AUTOSAR XML (schema 314)
package /DaVinci
  ecu configuration EPS: ecu-extract=EPS, ecu-sw-composition=EcuSwComposition
package /DaVinci/PKG_ClusterCAN00
  can cluster CAN00: nm-node-detection-enabled=false, nm-node-id-enabled=false, nm-repeat-message-support=false, speed=0
    physical channel CHNL: can-tp-connection-channel{addressing-format=STANDARD, data-pdu=DiagFuncReqFT_Tp__CAN00, multicast-addressing=true, tp-sdu=DCM_DiagFuncReqFT_Tp__CAN00}
      frame ABS2__CAN00: id 0x360, to EPS, frame-length=8, can-addressing-mode=STANDARD
        carries pdu ABS2__CAN00: packing-byte-order=big-endian, start-position=7
        pdu ABS2__CAN00: length=64
          signal VehSpeed_ABS2__CAN00: start 7, 12 bit, big-endian, data-type=DT_VehSpeed, init-value=C_VehSpeed, to EPS
      frame BCM1__CAN00: id 0x420, to EPS, frame-length=8, can-addressing-mode=STANDARD
        carries pdu BCM1__CAN00: packing-byte-order=big-endian, start-position=7
        pdu BCM1__CAN00: length=64
          signal BCM_Key_Sta_BCM1__CAN00: start 7, 2 bit, big-endian, data-type=DT_BCM_Key_Sta, init-value=C_BCM_Key_Sta, to EPS
      frame DiagFuncReqFT__CAN00: id 0x7D0, to EPS, frame-length=8, can-addressing-mode=STANDARD
        n pdu DiagFuncReqFT_Tp__CAN00
      frame DiagPhysReqToEPAS__CAN00: id 0x772, to EPS, frame-length=8, can-addressing-mode=STANDARD
        pdu DiagPhysReqToEPAS_Tp__CAN00: length=64
      frame DiagRespFromEPAS__CAN00: id 0x7B2, from EPS, frame-length=8, can-addressing-mode=STANDARD
        pdu DiagRespFromEPAS_Tp__CAN00: length=64
      frame ECM1__CAN00: id 0x316, to EPS, frame-length=8, can-addressing-mode=STANDARD
        carries pdu ECM1__CAN00: packing-byte-order=big-endian, start-position=7
        pdu ECM1__CAN00: length=64
          signal CAN_N_ECM1__CAN00: start 23, 16 bit, big-endian, data-type=DT_CAN_N, init-value=C_CAN_N, to EPS
          signal LV_CAN_N_ERR_ECM1__CAN00: start 1, 1 bit, big-endian, data-type=DT_LV_CAN_N_ERR, init-value=C_LV_CAN_N_ERR, to EPS
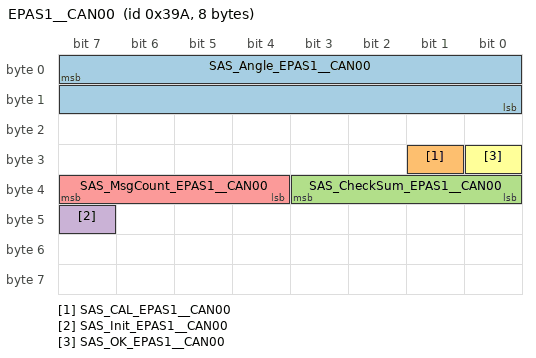
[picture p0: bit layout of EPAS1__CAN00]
      frame EPAS1__CAN00: id 0x39A, from EPS, frame-length=8, can-addressing-mode=STANDARD
        carries pdu EPAS1__CAN00: packing-byte-order=big-endian, start-position=7
        pdu EPAS1__CAN00: length=64, cyclic-timing=repeating-time=0
          transmission-mode-conditions:
            signal-in-i-pdu=SAS_Angle
            signal-in-i-pdu=SAS_CAL
            signal-in-i-pdu=SAS_CheckSum
            signal-in-i-pdu=SAS_Init
            signal-in-i-pdu=SAS_MsgCount
            signal-in-i-pdu=SAS_OK
          signal SAS_Angle_EPAS1__CAN00: start 7, 16 bit, big-endian, data-type=DT_SAS_Angle, init-value=C_SAS_Angle, transfer-property=PENDING
          signal SAS_CAL_EPAS1__CAN00: start 25, 1 bit, big-endian, data-type=DT_SAS_CAL, init-value=C_SAS_CAL, transfer-property=PENDING
          signal SAS_CheckSum_EPAS1__CAN00: start 35, 4 bit, big-endian, data-type=DT_SAS_CheckSum, init-value=C_SAS_CheckSum, transfer-property=PENDING
          signal SAS_Init_EPAS1__CAN00: start 47, 1 bit, big-endian, data-type=DT_SAS_Init, init-value=C_SAS_Init, transfer-property=PENDING
          signal SAS_MsgCount_EPAS1__CAN00: start 39, 4 bit, big-endian, data-type=DT_SAS_MsgCount, init-value=C_SAS_MsgCount, transfer-property=PENDING
          signal SAS_OK_EPAS1__CAN00: start 24, 1 bit, big-endian, data-type=DT_SAS_OK, init-value=C_SAS_OK, transfer-property=PENDING
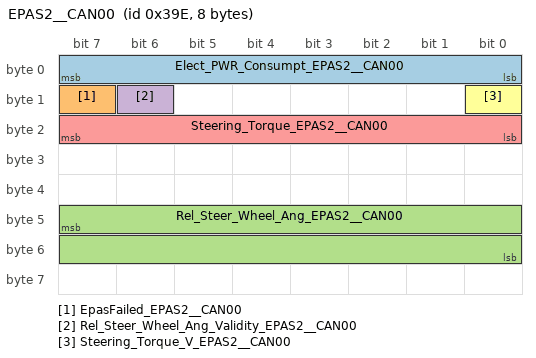
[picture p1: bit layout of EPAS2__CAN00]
      frame EPAS2__CAN00: id 0x39E, from EPS, frame-length=8, can-addressing-mode=STANDARD
        carries pdu EPAS2__CAN00: packing-byte-order=big-endian, start-position=7
        pdu EPAS2__CAN00: length=64, cyclic-timing=repeating-time=0
          transmission-mode-conditions:
            signal-in-i-pdu=Elect_PWR_Consumpt
            signal-in-i-pdu=EpasFailed
            signal-in-i-pdu=Rel_Steer_Wheel_Ang
            signal-in-i-pdu=Rel_Steer_Wheel_Ang_Validity
            signal-in-i-pdu=Steering_Torque
            signal-in-i-pdu=Steering_Torque_V
          signal Elect_PWR_Consumpt_EPAS2__CAN00: start 7, 8 bit, big-endian, data-type=DT_Elect_PWR_Consumpt, init-value=C_Elect_PWR_Consumpt, transfer-property=PENDING
          signal EpasFailed_EPAS2__CAN00: start 15, 1 bit, big-endian, data-type=DT_EpasFailed, init-value=C_EpasFailed, transfer-property=PENDING
          signal Rel_Steer_Wheel_Ang_EPAS2__CAN00: start 47, 16 bit, big-endian, transfer-property=PENDING
          signal Rel_Steer_Wheel_Ang_Validity_EPAS2__CAN00: start 14, 1 bit, big-endian, transfer-property=PENDING
          signal Steering_Torque_EPAS2__CAN00: start 23, 8 bit, big-endian, data-type=DT_Steering_Torque, init-value=C_Steering_Torque, transfer-property=PENDING
          signal Steering_Torque_V_EPAS2__CAN00: start 8, 1 bit, big-endian, data-type=DT_Steering_Torque_V, init-value=C_Steering_Torque_V, transfer-property=PENDING
      frame GliwaMaster__CAN00: id 0x7F0, to EPS, frame-length=8, can-addressing-mode=STANDARD
        pdu GliwaMaster__CAN00: length=64
      frame GliwaSlave__CAN00: id 0x7F1, from EPS, frame-length=8, can-addressing-mode=STANDARD
        pdu GliwaSlave__CAN00: length=64
      frame NMmBCM__CAN00: id 0x700, to EPS, frame-length=8, can-addressing-mode=STANDARD
        pdu NMmBCM__CAN00: length=64
      frame NMmEPAS__CAN00: id 0x707, from EPS, frame-length=8, can-addressing-mode=STANDARD
        pdu NMmEPAS__CAN00: length=64
      frame XcpMaster__CAN00: id 0x695, to EPS, frame-length=8, can-addressing-mode=STANDARD
        pdu XcpMaster__CAN00: length=64
      frame XcpSlave__CAN00: id 0x6E5, from EPS, frame-length=8, can-addressing-mode=STANDARD
        pdu XcpSlave__CAN00: length=64
      pdu triggering DCM_DiagFuncReqFT_Tp__CAN00_P: pdu=DCM_DiagFuncReqFT_Tp__CAN00, to EPS
package /DaVinci/PKG_ClusterCAN00/PKG_PDU
  dcm i pdu DCM_DiagFuncReqFT_Tp__CAN00
package /DaVinci/PKG_ECU
  ecu instance EPS: associated-i-pdu-group=[EPS_CAN00_Rx, EPS_CAN00_Tx], com-processing-period=0.001, diagnostic-address=0, sleep-mode-supported=false, wake-up-over-bus-supported=false
    can communication controller CAN00
    communication connector CAN00_EPS: channel=CHNL, comm-controller=CAN00
package /DaVinci/PKG_PDUGroup
  i pdu group EPS_CAN00_Rx: communication-direction=IN, i-pdu=[ABS2__CAN00, BCM1__CAN00, ECM1__CAN00]
  i pdu group EPS_CAN00_Tx: communication-direction=OUT, i-pdu=[DiagRespFromEPAS_Tp__CAN00, GliwaSlave__CAN00, NMmEPAS__CAN00, XcpSlave__CAN00, EPAS1__CAN00, EPAS2__CAN00]
package /ECUComposition
  ecu sw composition EcuSwComposition: ecu-extract=EPS
    9 x service component prototype:
      CDD: service-component=CDD
      ComM: service-component=ComM
      Dcm: service-component=Dcm
      Dem: service-component=Dem
      EcuM: service-component=EcuM
      NexteerLibs: service-component=NexteerLibs
      NvM: service-component=NvM
      NvMProxy: service-component=NvMProxy
      WdgM: service-component=WdgM
    service connector prototype NvMProxy_PS_NvMP_NvmBlock_EOLVehCntrOffset_AbsHwPos_EOLVehCntrOffset: application-port=ECU_Composition.AbsHwPos.EOLVehCntrOffset, service-port=NvMProxy.PS_NvMP_NvmBlock_EOLVehCntrOffset
    service connector prototype NexteerLibs_SystemTime_ActivePull_SystemTime: application-port=ECU_Composition.ActivePull.SystemTime, service-port=NexteerLibs.SystemTime
    service connector prototype NvMProxy_PS_NvMP_NvmBlock_SteerAsstDefeat_AstLmt_SteeringAsstDefeat: application-port=ECU_Composition.AstLmt.SteeringAsstDefeat, service-port=NvMProxy.PS_NvMP_NvmBlock_SteerAsstDefeat
    service connector prototype NvM_PS_Rte_NvmBlock_AvgFricLrn_AvgFricLrnData_AvgFricLrn_AvgFricLrnData: application-port=ECU_Composition.AvgFricLrn.AvgFricLrnData, service-port=NvM.PS_Rte_NvmBlock_AvgFricLrn_AvgFricLrnData
    service connector prototype NexteerLibs_SystemTime_AvgFricLrn_SystemTime: application-port=ECU_Composition.AvgFricLrn.SystemTime, service-port=NexteerLibs.SystemTime
    service connector prototype NvM_PS_Rte_NvmBlock_BatteryVoltage_OvervoltageData_BatteryVoltage_OvervoltageData: application-port=ECU_Composition.BatteryVoltage.OvervoltageData, service-port=NvM.PS_Rte_NvmBlock_BatteryVoltage_OvervoltageData
    service connector prototype NexteerLibs_SystemTime_BatteryVoltage_SystemTime: application-port=ECU_Composition.BatteryVoltage.SystemTime, service-port=NexteerLibs.SystemTime
    service connector prototype NexteerLibs_SystemTime_BkCpPc_SystemTime: application-port=ECU_Composition.BkCpPc.SystemTime, service-port=NexteerLibs.SystemTime
    service connector prototype NexteerLibs_SystemTime_BVDiag_SystemTime: application-port=ECU_Composition.BVDiag.SystemTime, service-port=NexteerLibs.SystemTime
    service connector prototype CDD_CDDPorts_CDDInterface_CDDPorts: application-port=ECU_Composition.CDDInterface.CDDPorts, service-port=CDD.CDDPorts
    service connector prototype WdgM_SE000_SE_100ms_10_CP001_ChkPtAp10_100msEnd_CP_ChkPtAp10_ChkPtAp10_100msEnd_CP: application-port=ECU_Composition.ChkPtAp10.ChkPtAp10_100msEnd_CP, service-port=WdgM.SE000_SE_100ms_10_CP001_ChkPtAp10_100msEnd_CP
    service connector prototype WdgM_SE000_SE_100ms_10_CP000_ChkPtAp10_100msStart_CP_ChkPtAp10_ChkPtAp10_100msStart_CP: application-port=ECU_Composition.ChkPtAp10.ChkPtAp10_100msStart_CP, service-port=WdgM.SE000_SE_100ms_10_CP000_ChkPtAp10_100msStart_CP
    service connector prototype WdgM_SE003_SE_10ms_10_CP001_ChkPtAp10_10msEnd_CP_ChkPtAp10_ChkPtAp10_10msEnd_CP: application-port=ECU_Composition.ChkPtAp10.ChkPtAp10_10msEnd_CP, service-port=WdgM.SE003_SE_10ms_10_CP001_ChkPtAp10_10msEnd_CP
    service connector prototype WdgM_SE003_SE_10ms_10_CP000_ChkPtAp10_10msStart_CP_ChkPtAp10_ChkPtAp10_10msStart_CP: application-port=ECU_Composition.ChkPtAp10.ChkPtAp10_10msStart_CP, service-port=WdgM.SE003_SE_10ms_10_CP000_ChkPtAp10_10msStart_CP
    service connector prototype WdgM_SE007_SE_2ms_10_CP001_ChkPtAp10_2msEnd_CP_ChkPtAp10_ChkPtAp10_2msEnd_CP: application-port=ECU_Composition.ChkPtAp10.ChkPtAp10_2msEnd_CP, service-port=WdgM.SE007_SE_2ms_10_CP001_ChkPtAp10_2msEnd_CP
    service connector prototype WdgM_SE007_SE_2ms_10_CP000_ChkPtAp10_2msStart_CP_ChkPtAp10_ChkPtAp10_2msStart_CP: application-port=ECU_Composition.ChkPtAp10.ChkPtAp10_2msStart_CP, service-port=WdgM.SE007_SE_2ms_10_CP000_ChkPtAp10_2msStart_CP
    service connector prototype WdgM_SE005_SE_4ms_10_CP001_ChkPtAp10_4msEnd_CP_ChkPtAp10_ChkPtAp10_4msEnd_CP: application-port=ECU_Composition.ChkPtAp10.ChkPtAp10_4msEnd_CP, service-port=WdgM.SE005_SE_4ms_10_CP001_ChkPtAp10_4msEnd_CP
    service connector prototype WdgM_SE005_SE_4ms_10_CP000_ChkPtAp10_4msStart_CP_ChkPtAp10_ChkPtAp10_4msStart_CP: application-port=ECU_Composition.ChkPtAp10.ChkPtAp10_4msStart_CP, service-port=WdgM.SE005_SE_4ms_10_CP000_ChkPtAp10_4msStart_CP
    service connector prototype WdgM_SE001_SE_100ms_8_CP001_ChkPtAp8_100msEnd_CP_ChkPtAp8_ChkPtAp8_100msEnd_CP: application-port=ECU_Composition.ChkPtAp8.ChkPtAp8_100msEnd_CP, service-port=WdgM.SE001_SE_100ms_8_CP001_ChkPtAp8_100msEnd_CP
    service connector prototype WdgM_SE001_SE_100ms_8_CP000_ChkPtAp8_100msStart_CP_ChkPtAp8_ChkPtAp8_100msStart_CP: application-port=ECU_Composition.ChkPtAp8.ChkPtAp8_100msStart_CP, service-port=WdgM.SE001_SE_100ms_8_CP000_ChkPtAp8_100msStart_CP
    service connector prototype WdgM_SE008_SE_2ms_8_CP001_ChkPtAp8_2msEnd_CP_ChkPtAp8_ChkPtAp8_2msEnd_CP: application-port=ECU_Composition.ChkPtAp8.ChkPtAp8_2msEnd_CP, service-port=WdgM.SE008_SE_2ms_8_CP001_ChkPtAp8_2msEnd_CP
    service connector prototype WdgM_SE008_SE_2ms_8_CP000_ChkPtAp8_2msStart_CP_ChkPtAp8_ChkPtAp8_2msStart_CP: application-port=ECU_Composition.ChkPtAp8.ChkPtAp8_2msStart_CP, service-port=WdgM.SE008_SE_2ms_8_CP000_ChkPtAp8_2msStart_CP
    service connector prototype WdgM_SE002_SE_100ms_9_CP001_ChkPtAp9_100msEnd_CP_ChkPtAp9_ChkPtAp9_100msEnd_CP: application-port=ECU_Composition.ChkPtAp9.ChkPtAp9_100msEnd_CP, service-port=WdgM.SE002_SE_100ms_9_CP001_ChkPtAp9_100msEnd_CP
    service connector prototype WdgM_SE002_SE_100ms_9_CP000_ChkPtAp9_100msStart_CP_ChkPtAp9_ChkPtAp9_100msStart_CP: application-port=ECU_Composition.ChkPtAp9.ChkPtAp9_100msStart_CP, service-port=WdgM.SE002_SE_100ms_9_CP000_ChkPtAp9_100msStart_CP
    service connector prototype WdgM_SE004_SE_10ms_9_CP001_ChkPtAp9_10msEnd_CP_ChkPtAp9_ChkPtAp9_10msEnd_CP: application-port=ECU_Composition.ChkPtAp9.ChkPtAp9_10msEnd_CP, service-port=WdgM.SE004_SE_10ms_9_CP001_ChkPtAp9_10msEnd_CP
    service connector prototype WdgM_SE004_SE_10ms_9_CP000_ChkPtAp9_10msStart_CP_ChkPtAp9_ChkPtAp9_10msStart_CP: application-port=ECU_Composition.ChkPtAp9.ChkPtAp9_10msStart_CP, service-port=WdgM.SE004_SE_10ms_9_CP000_ChkPtAp9_10msStart_CP
    service connector prototype WdgM_SE009_SE_2ms_9_CP001_ChkPtAp9_2msEnd_CP_ChkPtAp9_ChkPtAp9_2msEnd_CP: application-port=ECU_Composition.ChkPtAp9.ChkPtAp9_2msEnd_CP, service-port=WdgM.SE009_SE_2ms_9_CP001_ChkPtAp9_2msEnd_CP
    service connector prototype WdgM_SE009_SE_2ms_9_CP000_ChkPtAp9_2msStart_CP_ChkPtAp9_ChkPtAp9_2msStart_CP: application-port=ECU_Composition.ChkPtAp9.ChkPtAp9_2msStart_CP, service-port=WdgM.SE009_SE_2ms_9_CP000_ChkPtAp9_2msStart_CP
    service connector prototype WdgM_SE006_SE_4ms_9_CP001_ChkPtAp9_4msEnd_CP_ChkPtAp9_ChkPtAp9_4msEnd_CP: application-port=ECU_Composition.ChkPtAp9.ChkPtAp9_4msEnd_CP, service-port=WdgM.SE006_SE_4ms_9_CP001_ChkPtAp9_4msEnd_CP
    service connector prototype WdgM_SE006_SE_4ms_9_CP000_ChkPtAp9_4msStart_CP_ChkPtAp9_ChkPtAp9_4msStart_CP: application-port=ECU_Composition.ChkPtAp9.ChkPtAp9_4msStart_CP, service-port=WdgM.SE006_SE_4ms_9_CP000_ChkPtAp9_4msStart_CP
    service connector prototype NvMProxy_PS_NvMP_NvmBlock_CurrTempOffset_CmMtrCurr_EOLCurrTempOffset: application-port=ECU_Composition.CmMtrCurr.EOLCurrTempOffset, service-port=NvMProxy.PS_NvMP_NvmBlock_CurrTempOffset
    service connector prototype NvMProxy_PS_NvMP_NvmBlock_ShCurrCal_CmMtrCurr_EOLShCurrCal: application-port=ECU_Composition.CmMtrCurr.EOLShCurrCal, service-port=NvMProxy.PS_NvMP_NvmBlock_ShCurrCal
    service connector prototype NexteerLibs_SystemTime_ComplErr_SystemTime: application-port=ECU_Composition.ComplErr.SystemTime, service-port=NexteerLibs.SystemTime
    service connector prototype NexteerLibs_SystemTime_CtrldDisShtdn_SystemTime: application-port=ECU_Composition.CtrldDisShtdn.SystemTime, service-port=NexteerLibs.SystemTime
    service connector prototype NvMProxy_PS_NvMP_NvmBlock_EOLNomMtrParam_CurrParamComp_EOLNomMtrParamBlk: application-port=ECU_Composition.CurrParamComp.EOLNomMtrParamBlk, service-port=NvMProxy.PS_NvMP_NvmBlock_EOLNomMtrParam
    service connector prototype Dcm_DCMServices_DiagSvc_DCMServices: application-port=ECU_Composition.DiagSvc.DCMServices, service-port=Dcm.DCMServices
    service connector prototype Dcm_DidServices_0x0100_DiagSvc_DidServices_0x0100: application-port=ECU_Composition.DiagSvc.DidServices_0x0100, service-port=Dcm.DidServices_0x0100
    service connector prototype Dcm_DidServices_0xf180_DiagSvc_DidServices_0xf180: application-port=ECU_Composition.DiagSvc.DidServices_0xf180, service-port=Dcm.DidServices_0xf180
    service connector prototype Dcm_DidServices_0xf187_DiagSvc_DidServices_0xf187: application-port=ECU_Composition.DiagSvc.DidServices_0xf187, service-port=Dcm.DidServices_0xf187
    service connector prototype Dcm_DidServices_0xf18a_DiagSvc_DidServices_0xf18a: application-port=ECU_Composition.DiagSvc.DidServices_0xf18a, service-port=Dcm.DidServices_0xf18a
    service connector prototype Dcm_DidServices_0xf18c_DiagSvc_DidServices_0xf18c: application-port=ECU_Composition.DiagSvc.DidServices_0xf18c, service-port=Dcm.DidServices_0xf18c
    service connector prototype Dcm_DidServices_0xf191_DiagSvc_DidServices_0xf191: application-port=ECU_Composition.DiagSvc.DidServices_0xf191, service-port=Dcm.DidServices_0xf191
    service connector prototype Dcm_DidServices_0xf{193..195}_DiagSvc_DidServices_0xf{193..195}: application-port=ECU_Composition.DiagSvc.DidServices_0xf{193..195}, service-port=Dcm.DidServices_0xf{193..195}
    service connector prototype Dcm_DidServices_0xfd01_DiagSvc_DidServices_0xfd01: application-port=ECU_Composition.DiagSvc.DidServices_0xfd01, service-port=Dcm.DidServices_0xfd01
    service connector prototype Dcm_DidServices_0xfd02_DiagSvc_DidServices_0xfd02: application-port=ECU_Composition.DiagSvc.DidServices_0xfd02, service-port=Dcm.DidServices_0xfd02
    service connector prototype Dcm_DidServices_0xfd07_DiagSvc_DidServices_0xfd07: application-port=ECU_Composition.DiagSvc.DidServices_0xfd07, service-port=Dcm.DidServices_0xfd07
    service connector prototype Dcm_DidServices_0xfd0d_DiagSvc_DidServices_0xfd0d: application-port=ECU_Composition.DiagSvc.DidServices_0xfd0d, service-port=Dcm.DidServices_0xfd0d
    service connector prototype Dcm_DidServices_0xfd0e_DiagSvc_DidServices_0xfd0e: application-port=ECU_Composition.DiagSvc.DidServices_0xfd0e, service-port=Dcm.DidServices_0xfd0e
    service connector prototype Dcm_DidServices_0xfd{10..14}_DiagSvc_DidServices_0xfd{10..14}: application-port=ECU_Composition.DiagSvc.DidServices_0xfd{10..14}, service-port=Dcm.DidServices_0xfd{10..14}
    service connector prototype Dcm_DidServices_0xfd17_DiagSvc_DidServices_0xfd17: application-port=ECU_Composition.DiagSvc.DidServices_0xfd17, service-port=Dcm.DidServices_0xfd17
    service connector prototype Dcm_DidServices_0xfd19_DiagSvc_DidServices_0xfd19: application-port=ECU_Composition.DiagSvc.DidServices_0xfd19, service-port=Dcm.DidServices_0xfd19
    service connector prototype Dcm_DidServices_0xfd1a_DiagSvc_DidServices_0xfd1a: application-port=ECU_Composition.DiagSvc.DidServices_0xfd1a, service-port=Dcm.DidServices_0xfd1a
    service connector prototype Dcm_DidServices_0xfd1b_DiagSvc_DidServices_0xfd1b: application-port=ECU_Composition.DiagSvc.DidServices_0xfd1b, service-port=Dcm.DidServices_0xfd1b
    service connector prototype Dcm_DidServices_0xfd1c_DiagSvc_DidServices_0xfd1c: application-port=ECU_Composition.DiagSvc.DidServices_0xfd1c, service-port=Dcm.DidServices_0xfd1c
    service connector prototype Dcm_DidServices_0xfd1e_DiagSvc_DidServices_0xfd1e: application-port=ECU_Composition.DiagSvc.DidServices_0xfd1e, service-port=Dcm.DidServices_0xfd1e
    service connector prototype Dcm_DidServices_0xfd20_DiagSvc_DidServices_0xfd20: application-port=ECU_Composition.DiagSvc.DidServices_0xfd20, service-port=Dcm.DidServices_0xfd20
    service connector prototype Dcm_DidServices_0xfd21_DiagSvc_DidServices_0xfd21: application-port=ECU_Composition.DiagSvc.DidServices_0xfd21, service-port=Dcm.DidServices_0xfd21
    service connector prototype Dcm_DidServices_0xfd23_DiagSvc_DidServices_0xfd23: application-port=ECU_Composition.DiagSvc.DidServices_0xfd23, service-port=Dcm.DidServices_0xfd23
    service connector prototype Dcm_DidServices_0xfd{25..27}_DiagSvc_DidServices_0xfd{25..27}: application-port=ECU_Composition.DiagSvc.DidServices_0xfd{25..27}, service-port=Dcm.DidServices_0xfd{25..27}
    service connector prototype Dcm_DidServices_0xfd{29..31}_DiagSvc_DidServices_0xfd{29..31}: application-port=ECU_Composition.DiagSvc.DidServices_0xfd{29..31}, service-port=Dcm.DidServices_0xfd{29..31}
    service connector prototype Dcm_DidServices_0xfda{1..3}_DiagSvc_DidServices_0xfda{1..3}: application-port=ECU_Composition.DiagSvc.DidServices_0xfda{1..3}, service-port=Dcm.DidServices_0xfda{1..3}
    service connector prototype Dcm_DidServices_0xfdac_DiagSvc_DidServices_0xfdac: application-port=ECU_Composition.DiagSvc.DidServices_0xfdac, service-port=Dcm.DidServices_0xfdac
    service connector prototype Dcm_DidServices_0xfdad_DiagSvc_DidServices_0xfdad: application-port=ECU_Composition.DiagSvc.DidServices_0xfdad, service-port=Dcm.DidServices_0xfdad
    service connector prototype Dcm_DidServices_0xfdae_DiagSvc_DidServices_0xfdae: application-port=ECU_Composition.DiagSvc.DidServices_0xfdae, service-port=Dcm.DidServices_0xfdae
    service connector prototype Dcm_DidServices_0xfdaf_DiagSvc_DidServices_0xfdaf: application-port=ECU_Composition.DiagSvc.DidServices_0xfdaf, service-port=Dcm.DidServices_0xfdaf
    service connector prototype Dcm_DidServices_0xfdb{0..7}_DiagSvc_DidServices_0xfdb{0..7}: application-port=ECU_Composition.DiagSvc.DidServices_0xfdb{0..7}, service-port=Dcm.DidServices_0xfdb{0..7}
    service connector prototype Dcm_DidServices_0xfe00_DiagSvc_DidServices_0xfe00: application-port=ECU_Composition.DiagSvc.DidServices_0xfe00, service-port=Dcm.DidServices_0xfe00
    service connector prototype NvM_PS_NVM_BLOCK_CMS_ECUHWPN_DiagSvc_ECUHardwareNumber: application-port=ECU_Composition.DiagSvc.ECUHardwareNumber, service-port=NvM.PS_NVM_BLOCK_CMS_ECUHWPN
    service connector prototype NvM_PS_NVM_BLOCK_CMS_ECUSRLNUM_DiagSvc_ECUSerialNumber: application-port=ECU_Composition.DiagSvc.ECUSerialNumber, service-port=NvM.PS_NVM_BLOCK_CMS_ECUSRLNUM
    service connector prototype Dcm_RoutineServices_0xf000_DiagSvc_RoutineServices_0xf000: application-port=ECU_Composition.DiagSvc.RoutineServices_0xf000, service-port=Dcm.RoutineServices_0xf000
    service connector prototype Dcm_RoutineServices_0xf001_DiagSvc_RoutineServices_0xf001: application-port=ECU_Composition.DiagSvc.RoutineServices_0xf001, service-port=Dcm.RoutineServices_0xf001
    service connector prototype Dcm_RoutineServices_0xf{003..005}_DiagSvc_RoutineServices_0xf{003..005}: application-port=ECU_Composition.DiagSvc.RoutineServices_0xf{003..005}, service-port=Dcm.RoutineServices_0xf{003..005}
    service connector prototype Dcm_RoutineServices_0xf008_DiagSvc_RoutineServices_0xf008: application-port=ECU_Composition.DiagSvc.RoutineServices_0xf008, service-port=Dcm.RoutineServices_0xf008
    service connector prototype Dcm_RoutineServices_0xf009_DiagSvc_RoutineServices_0xf009: application-port=ECU_Composition.DiagSvc.RoutineServices_0xf009, service-port=Dcm.RoutineServices_0xf009
    service connector prototype Dcm_RoutineServices_0xf0ff_DiagSvc_RoutineServices_0xf0ff: application-port=ECU_Composition.DiagSvc.RoutineServices_0xf0ff, service-port=Dcm.RoutineServices_0xf0ff
    service connector prototype Dcm_RoutineServices_0xfee0_DiagSvc_RoutineServices_0xfee0: application-port=ECU_Composition.DiagSvc.RoutineServices_0xfee0, service-port=Dcm.RoutineServices_0xfee0
    service connector prototype Dcm_SecurityAccess_1_DiagSvc_SecurityAccess_1: application-port=ECU_Composition.DiagSvc.SecurityAccess_1, service-port=Dcm.SecurityAccess_1
    service connector prototype Dcm_SessionControl_DiagSvc_SessionControl: application-port=ECU_Composition.DiagSvc.SessionControl, service-port=Dcm.SessionControl
    service connector prototype NvM_PS_Rte_NvmBlock_DiagSvc_SparePartNumberData_DiagSvc_SparePartNumber: application-port=ECU_Composition.DiagSvc.SparePartNumber, service-port=NvM.PS_Rte_NvmBlock_DiagSvc_SparePartNumberData
    service connector prototype NvM_PS_Rte_NvmBlock_DiagSvc_SupplierIdentifierData_DiagSvc_SupplierIdentifier: application-port=ECU_Composition.DiagSvc.SupplierIdentifier, service-port=NvM.PS_Rte_NvmBlock_DiagSvc_SupplierIdentifierData
    service connector prototype NvM_PS_Rte_NvmBlock_DiagSvc_TuningSetSelectData_DiagSvc_TuningSetSelect: application-port=ECU_Composition.DiagSvc.TuningSetSelect, service-port=NvM.PS_Rte_NvmBlock_DiagSvc_TuningSetSelectData
    service connector prototype NvMProxy_PS_NvMP_NvmBlock_DigTrqTrim_DigHwTrqSENT_NvM_DigHwTrqSENTTrim_Srv: application-port=ECU_Composition.DigHwTrqSENT.NvM_DigHwTrqSENTTrim_Srv, service-port=NvMProxy.PS_NvMP_NvmBlock_DigTrqTrim
    service connector prototype NexteerLibs_SystemTime_FltInjection_SystemTime: application-port=ECU_Composition.FltInjection.SystemTime, service-port=NexteerLibs.SystemTime
    service connector prototype NvM_PS_Rte_NvmBlock_LrnEOT_LearnedEOT_LrnEOT_LearnedEOTData: application-port=ECU_Composition.LrnEOT.LearnedEOTData, service-port=NvM.PS_Rte_NvmBlock_LrnEOT_LearnedEOT
    service connector prototype NexteerLibs_SystemTime_LrnEOT_SystemTime: application-port=ECU_Composition.LrnEOT.SystemTime, service-port=NexteerLibs.SystemTime
    service connector prototype NexteerLibs_SystemTime_MtrDrvDiag_SystemTime: application-port=ECU_Composition.MtrDrvDiag.SystemTime, service-port=NexteerLibs.SystemTime
    service connector prototype NvMProxy_PS_NvMP_NvmBlock_Polarity_Polarity_Polarity: application-port=ECU_Composition.Polarity.Polarity, service-port=NvMProxy.PS_NvMP_NvmBlock_Polarity
    service connector prototype NexteerLibs_SystemTime_PwrLmtFuncCr_SystemTime: application-port=ECU_Composition.PwrLmtFuncCr.SystemTime, service-port=NexteerLibs.SystemTime
    service connector prototype NexteerLibs_SystemTime_SrlComInput_SystemTime: application-port=ECU_Composition.SrlComInput.SystemTime, service-port=NexteerLibs.SystemTime
    service connector prototype ComM_UR_ComMUser_CAN00_SrlComOutput_ComM_UserRequest: application-port=ECU_Composition.SrlComOutput.ComM_UserRequest, service-port=ComM.UR_ComMUser_CAN00
    service connector prototype Dem_IndStatus_EpasFailed_SrlComOutput_EpasFailed: application-port=ECU_Composition.SrlComOutput.EpasFailed, service-port=Dem.IndStatus_EpasFailed
    service connector prototype NexteerLibs_SystemTime_SrlComOutput_SystemTime: application-port=ECU_Composition.SrlComOutput.SystemTime, service-port=NexteerLibs.SystemTime
    service connector prototype NvMProxy_PS_NvMP_NvmBlock_CloseCheckData_StaMd_CloseCheckData: application-port=ECU_Composition.StaMd.CloseCheckData, service-port=NvMProxy.PS_NvMP_NvmBlock_CloseCheckData
    service connector prototype NvMProxy_PS_NvMP_NvmBlock_TypeHRamBuffer_StaMd_TypeHData: application-port=ECU_Composition.StaMd.TypeHData, service-port=NvMProxy.PS_NvMP_NvmBlock_TypeHRamBuffer
    service connector prototype NexteerLibs_SystemTime_StOpCtrl_SystemTime: application-port=ECU_Composition.StOpCtrl.SystemTime, service-port=NexteerLibs.SystemTime
    service connector prototype NexteerLibs_SystemTime_Sweep_SystemTime: application-port=ECU_Composition.Sweep.SystemTime, service-port=NexteerLibs.SystemTime
    service connector prototype NvM_PS_Rte_NvmBlock_ThrmlDutyCycle_ThrmlDutyCycle_FltStVal_ThrmlDutyCycle_ThrmlDutyCycle_FltStVar: application-port=ECU_Composition.ThrmlDutyCycle.ThrmlDutyCycle_FltStVar, service-port=NvM.PS_Rte_NvmBlock_ThrmlDutyCycle_ThrmlDutyCycle_FltStVal
    service connector prototype NexteerLibs_SystemTime_TmprlMon_SystemTime: application-port=ECU_Composition.TmprlMon.SystemTime, service-port=NexteerLibs.SystemTime
    service connector prototype NexteerLibs_SystemTime_TmprlMon2_SystemTime: application-port=ECU_Composition.TmprlMon2.SystemTime, service-port=NexteerLibs.SystemTime
    service connector prototype NvMProxy_PS_NvMP_NvmBlock_CogTrqCal_TrqCanc_EOLCogTrqCanc: application-port=ECU_Composition.TrqCanc.EOLCogTrqCanc, service-port=NvMProxy.PS_NvMP_NvmBlock_CogTrqCal
    service connector prototype NvMProxy_PS_NvMP_NvmBlock_CogTrqRplComp_TrqCanc_EOLCogTrqRplComp: application-port=ECU_Composition.TrqCanc.EOLCogTrqRplComp, service-port=NvMProxy.PS_NvMP_NvmBlock_CogTrqRplComp
    service connector prototype NvMProxy_PS_NvMP_NvmBlock_TorqueCmdSF_TrqCmdScl_TrqCmdScl: application-port=ECU_Composition.TrqCmdScl.TrqCmdScl, service-port=NvMProxy.PS_NvMP_NvmBlock_TorqueCmdSF
    service connector prototype NvMProxy_PS_NvMP_NvmBlock_MotPosReset_VehDyn_NVM_VehDynReset_Srv: application-port=ECU_Composition.VehDyn.NVM_VehDynReset_Srv, service-port=NvMProxy.PS_NvMP_NvmBlock_MotPosReset
    service connector prototype NexteerLibs_SystemTime_VehDyn_SystemTime: application-port=ECU_Composition.VehDyn.SystemTime, service-port=NexteerLibs.SystemTime
    service connector prototype EcuM_EcuMUsrCfg_EPS_VehPwrMd_EpsEcuMStRqst: application-port=ECU_Composition.VehPwrMd.EpsEcuMStRqst, service-port=EcuM.EcuMUsrCfg_EPS
package /ECUCompositionType
  composition type ECU_Composition
    12 x provide port:
      Com_Elect_PWR_Consumpt: unqueued-sender-com-spec{data-element=Cnt_u08, can-invalidate=false, init-value=C_Elect_PWR_Consumpt}, provided-interface=Com_Elect_PWR_Consumpt
      Com_EpasFailed: unqueued-sender-com-spec{data-element=Cnt_lgc, can-invalidate=false, init-value=C_EpasFailed}, provided-interface=Com_EpasFailed
      Com_Rel_Steer_Wheel_Ang: unqueued-sender-com-spec{data-element=Cnt_u16, can-invalidate=false, init-value=C_RELSTRWHLANGINIT_CNT_U16}, provided-interface=Com_Rel_Steer_Wheel_Ang
      Com_Rel_Steer_Wheel_Ang_Validity: unqueued-sender-com-spec{data-element=Cnt_lgc, can-invalidate=false, init-value=C_RELSTRWHLANGVALIDINIT_CNT_LGC}, provided-interface=Com_Rel_Steer_Wheel_Ang_Validity
      Com_SAS_Angle: unqueued-sender-com-spec{data-element=Cnt_u16, can-invalidate=false, init-value=C_SAS_Angle}, provided-interface=Com_SAS_Angle
      Com_SAS_CAL: unqueued-sender-com-spec{data-element=Cnt_lgc, can-invalidate=false, init-value=C_SAS_CAL}, provided-interface=Com_SAS_CAL
      Com_SAS_CheckSum: unqueued-sender-com-spec{data-element=Cnt_u08, can-invalidate=false, init-value=C_SAS_CheckSum}, provided-interface=Com_SAS_CheckSum
      Com_SAS_Init: unqueued-sender-com-spec{data-element=Cnt_lgc, can-invalidate=false, init-value=C_SAS_Init}, provided-interface=Com_SAS_Init
      Com_SAS_MsgCount: unqueued-sender-com-spec{data-element=Cnt_u08, can-invalidate=false, init-value=C_SAS_MsgCount}, provided-interface=Com_SAS_MsgCount
      Com_SAS_OK: unqueued-sender-com-spec{data-element=Cnt_lgc, can-invalidate=false, init-value=C_SAS_OK}, provided-interface=Com_SAS_OK
      Com_Steering_Torque: unqueued-sender-com-spec{data-element=Cnt_u08, can-invalidate=false, init-value=C_Steering_Torque}, provided-interface=Com_Steering_Torque
      Com_Steering_Torque_V: unqueued-sender-com-spec{data-element=Cnt_lgc, can-invalidate=false, init-value=C_Steering_Torque_V}, provided-interface=Com_Steering_Torque_V
    4 x require port:
      Com_BCM_Key_Sta: unqueued-receiver-com-spec{data-element=Cnt_enum, init-value=C_BCM_Key_Sta}, required-interface=Com_BCM_Key_Sta
      Com_CAN_N: unqueued-receiver-com-spec{data-element=Cnt_u16, init-value=C_CAN_N}, required-interface=Com_CAN_N
      Com_LV_CAN_N_ERR: unqueued-receiver-com-spec{data-element=Cnt_lgc, init-value=C_LV_CAN_N_ERR}, required-interface=Com_LV_CAN_N_ERR
      Com_VehSpeed: unqueued-receiver-com-spec{data-element=Cnt_u16, init-value=C_VehSpeed}, required-interface=Com_VehSpeed
    87 x component:
      AbsHwPos: type=Ap_AbsHwPos
      ActivePull: type=Ap_ActivePull
      ApXcp: type=Ap_ApXcp
      Assist: type=Ap_Assist
      AssistFirewall: type=Ap_AssistFirewall
      AstLmt: type=Ap_AstLmt
      AvgFricLrn: type=Ap_AvgFricLrn
      BatteryVoltage: type=Ap_BatteryVoltage
      BkCpPc: type=Sa_BkCpPc
      BVDiag: type=Ap_BVDiag
      CDDInterface: type=Sa_CDDInterface
      ChkPtAp10: type=Ap_ChkPtAp10
      ChkPtAp8: type=Ap_ChkPtAp8
      ChkPtAp9: type=Ap_ChkPtAp9
      CmMtrCurr: type=Sa_CmMtrCurr
      ComplErr: type=Ap_ComplErr
      CtrldDisShtdn: type=Ap_CtrldDisShtdn
      CtrlTemp: type=Sa_CtrlTemp
      CurrCmd: type=Ap_CurrCmd
      CurrParamComp: type=Ap_CurrParamComp
      Damping: type=Ap_Damping
      DampingFirewall: type=Ap_DampingFirewall
      DemIf: type=Ap_DemIf
      DiagMgr10: type=Ap_DiagMgr10
      DiagMgr8: type=Ap_DiagMgr8
      DiagMgr9: type=Ap_DiagMgr9
      DiagSvc: type=Ap_DiagSvc
      DigHwTrqSENT: type=Sa_DigHwTrqSENT
      DigMSB: type=Sa_DigMSB
      DigPhsReasDiag: type=Ap_DigPhsReasDiag
      ElePwr: type=Ap_ElePwr
      EOTActuatorMng: type=Ap_EOTActuatorMng
      ePWM2: type=Ap_ePWM2
      EtDmpFw: type=Ap_EtDmpFw
      FltInjection: type=Ap_FltInjection
      FrqDepDmpnInrtCmp: type=Ap_FrqDepDmpnInrtCmp
      Gsod: type=Ap_Gsod
      HaitecTrqCmd: type=Ap_HaitecTrqCmd
      HighFreqAssist: type=Ap_HighFreqAssist
      HiLoadStall: type=Ap_HiLoadStall
      HwPwUp: type=Ap_HwPwUp
      HystComp: type=Ap_HystComp
      IoHwAbsDigSig: type=IoHwAbstraction
      IoHwAbstractionUsr: type=IoHwAbstractionUsr
      LmtCod: type=Ap_LmtCod
      LrnEOT: type=Ap_LrnEOT
      MtrDrvDiag: type=Sa_MtrDrvDiag
      MtrTempEst: type=Ap_MtrTempEst
      MtrVel: type=Sa_MtrVel
      MtrVel2: type=Sa_MtrVel2
      MtrVel3: type=Sa_MtrVel3
      Nhet1: type=Cd_Nhet1
      NtWrap: type=NtWrap
      OvrVoltMon: type=Sa_OvrVoltMon
      PeakCurrEst: type=Ap_PeakCurrEst
      PICurrCntrl: type=Ap_PICurrCntrl
      Polarity: type=Ap_Polarity
      PwrLmtFuncCr: type=Ap_PwrLmtFuncCr
      QuadDet: type=Ap_QuadDet
      Return: type=Ap_Return
      ReturnFirewall: type=Ap_ReturnFirewall
      RteErrata: type=RteErrata10
      RteErrata8: type=RteErrata8
      RteErrata9: type=RteErrata9
      ShtdnMech: type=Sa_ShtdnMech
      SignlCondn: type=Ap_SignlCondn
      SrlComInput: type=Ap_SrlComInput
      SrlComOutput: type=Ap_SrlComOutput
      StabilityComp: type=Ap_StabilityComp
      StabilityComp2: type=Ap_StabilityComp2
      StaMd: type=Ap_StaMd
      StaMd8: type=Ap_StaMd8
      StaMd9: type=Ap_StaMd9
      StOpCtrl: type=Ap_StOpCtrl
      Sweep: type=Ap_Sweep
      Sweep2: type=Ap_Sweep2
      ThrmlDutyCycle: type=Ap_ThrmlDutyCycle
      TmprlMon: type=Sa_TmprlMon
      TmprlMon2: type=Sa_TmprlMon2
      TqRsDg: type=Ap_TqRsDg
      TrqCanc: type=Ap_TrqCanc
      TrqCmdScl: type=Ap_TrqCmdScl
      TuningSelAuth: type=Ap_TuningSelAuth
      uDiag: type=Cd_uDiag
      VehDyn: type=Ap_VehDyn
      VehPwrMd: type=Ap_VehPwrMd
      VehSpdLmt: type=Ap_VehSpdLmt
    connect AbsHwPos.AbsHwPos_SCom -> NtWrap.C_AbsHwPos_SCom
    connect AbsHwPos.HandwheelAuthority -> ActivePull.HandwheelAuthority
    connect AbsHwPos.HandwheelAuthority -> AvgFricLrn.HwPosAuthority
    connect AbsHwPos.HandwheelAuthority -> EOTActuatorMng.HandWheelAuth
    connect AbsHwPos.HandwheelAuthority -> EtDmpFw.HandwheelAuthority
    connect AbsHwPos.HandwheelAuthority -> LrnEOT.HandwheelAuthority
    connect AbsHwPos.HandwheelAuthority -> Return.HandwheelAuthority
    connect AbsHwPos.HandwheelAuthority -> SrlComOutput.HandwheelAuthority
    connect AbsHwPos.HandwheelAuthority -> VehDyn.HwAuth
    connect AbsHwPos.HandwheelAuthority -> VehSpdLmt.HwPosAuth
    connect AbsHwPos.HandwheelPosition -> ActivePull.HandwheelPosition
    connect AbsHwPos.HandwheelPosition -> AvgFricLrn.HwAng
    connect AbsHwPos.HandwheelPosition -> EOTActuatorMng.HandWheelPos
    connect AbsHwPos.HandwheelPosition -> EtDmpFw.HandwheelPosition
    connect AbsHwPos.HandwheelPosition -> LrnEOT.HandwheelPosition
    connect AbsHwPos.HandwheelPosition -> Return.HandwheelPosition
    connect AbsHwPos.HandwheelPosition -> ReturnFirewall.HandwheelPosition
    connect AbsHwPos.HandwheelPosition -> SrlComOutput.HandwheelPosition
    connect AbsHwPos.HandwheelPosition -> VehDyn.HandwheelPosition
    connect AbsHwPos.HandwheelPosition -> VehSpdLmt.HwPos
    connect AbsHwPos.RelHwPos -> SrlComOutput.RelHwPos
    connect AbsHwPos.RelHwPos -> VehDyn.RelHwPos
    connect AbsHwPos.SrlComHwPosStatus -> SrlComOutput.SrlComHwPosStatus
    connect ActivePull.PullCompCmd -> AstLmt.PullCompCmd
    connect ApXcp.ActiveTunOvrPtrAddr -> TuningSelAuth.ActiveTunOvrPtrAddr
    connect ApXcp.TuningSessionActPtr -> TuningSelAuth.TuningSessionActPtr
    connect Assist.BaseAssistCmd -> AssistFirewall.BaseAssistCmd
    connect Assist.BaseAssistCmd -> DampingFirewall.BaseAssistCmd
    connect Assist.BaseAssistCmd -> FrqDepDmpnInrtCmp.BaseAssistCmd
    connect Assist.BaseAssistCmd -> HystComp.BaseAssistCmd
    connect AssistFirewall.AsstFirewallActive -> DampingFirewall.AsstFirewallActive
    connect AssistFirewall.AsstFirewallActive -> StabilityComp.AsstFWActive
    connect AssistFirewall.AsstFirewallActive -> StabilityComp2.AsstFWActive
    connect AssistFirewall.CombinedAssist -> StabilityComp.CombinedAssist
    connect AssistFirewall.CombinedAssist -> StabilityComp2.CombinedAssist
    connect AstLmt.AstLmt_Scom -> HaitecTrqCmd.AstLmt_Scom
    connect AstLmt.AstLmt_Scom -> NtWrap.C_AstLmt_Scom
    connect AstLmt.PreLimitForStall -> HiLoadStall.PreLimitForStall
    connect AstLmt.PreLimitTorque -> EOTActuatorMng.PreLimitTorque
    connect AstLmt.SumLimTrqCmd -> Sweep2.InputMtrTrq
    connect AstLmt.TrqLimitMin -> TqRsDg.TrqLimitMin
    connect AvgFricLrn.FricOffset -> HystComp.FricOffset
    connect BatteryVoltage.SysC_Vecu -> Gsod.SysC_Vecu
    connect BatteryVoltage.Vecu -> CDDInterface.Vecu
    connect BatteryVoltage.Vecu -> CmMtrCurr.Vecu
    connect BatteryVoltage.Vecu -> CurrCmd.Vecu
    connect BatteryVoltage.Vecu -> ElePwr.Vecu
    connect BatteryVoltage.Vecu -> Gsod.Vecu
    connect BatteryVoltage.Vecu -> PwrLmtFuncCr.Vecu
    connect BkCpPc.CapPcDcStub -> BkCpPc.PhyCapDischarge
    connect BkCpPc.CapPcDcStub -> BkCpPc.PhyCapPrecharge
    connect BkCpPc.PwrDiscATestComplete -> HwPwUp.PwrDiscATestComplete
    connect BkCpPc.PwrDiscBTestComplete -> HwPwUp.PwrDiscBTestComplete
    connect CDDInterface.ADCMtrCurr1 -> CmMtrCurr.ADCMtrCurr1
    connect CDDInterface.ADCMtrCurr2 -> CmMtrCurr.ADCMtrCurr2
    connect CDDInterface.CorrectedElecMtrPos -> DigMSB.CorrectedElecMtrPos
    connect CDDInterface.CorrMtrCurrPosition -> CmMtrCurr.CorrMtrCurrPosition
    connect CDDInterface.CorrMtrPosElec -> DigPhsReasDiag.LRPRCorrectedMtrPosCaptured
    connect CDDInterface.CorrMtrPosElec -> Gsod.Corrected_MtrPos
    connect CDDInterface.CorrMtrPosElec -> PICurrCntrl.CorrMtrPosElec
    connect CDDInterface.CumMechMtrPos -> DigMSB.CumMechMtrPos
    connect CDDInterface.DampingSrlComSvcDft -> Damping.DefeatDampingSvc
    connect CDDInterface.DampingSrlComSvcDft -> DampingFirewall.Defeat_Damping_Svc
    connect CDDInterface.DftAsstTbl -> Assist.DftAsstTbl
    connect CDDInterface.DftAsstTbl -> AssistFirewall.Defeat_AsstTbl_Service
    connect CDDInterface.Die1RxError -> DigMSB.Die1RxError
    connect CDDInterface.Die1RxMtrPos -> DigMSB.Die1RxMtrPos
    connect CDDInterface.Die1RxRevCtr -> DigMSB.Die1RxRevCtr
    connect CDDInterface.Die1UnderVoltgFltAccum -> DigMSB.Die1UnderVoltgFltAccum
    connect CDDInterface.Die2RxError -> DigMSB.Die2RxError
    connect CDDInterface.Die2RxMtrPos -> DigMSB.Die2RxMtrPos
    connect CDDInterface.Die2RxRevCtr -> DigMSB.Die2RxRevCtr
    connect CDDInterface.DwnldAsstGain -> Assist.DwnldAsstGain
    connect CDDInterface.EnergyModeState -> DigMSB.EnergyModeState
    connect CDDInterface.EngONSrlComSvcDft -> VehPwrMd.EngONSrlComSvcDft
    connect CDDInterface.EOTImpactSrlComSvcDft -> EOTActuatorMng.EOTDisable
    connect CDDInterface.EOTImpactSrlComSvcDft -> EtDmpFw.EOTDisable
    connect CDDInterface.EOTThermalSrlComSvcDft -> HiLoadStall.DftStallLimit
    connect CDDInterface.ExpectedOnTimeA -> DigPhsReasDiag.ExpectedOnTimeA
    connect CDDInterface.ExpectedOnTimeB -> DigPhsReasDiag.ExpectedOnTimeB
    connect CDDInterface.ExpectedOnTimeC -> DigPhsReasDiag.ExpectedOnTimeC
    connect CDDInterface.FreqDepDmpSrlComSvcDft -> DampingFirewall.FreqDepDmpSrlComSvcDft
    connect CDDInterface.FreqDepDmpSrlComSvcDft -> FrqDepDmpnInrtCmp.FreqDepDmpSrlComSvcDft
    connect CDDInterface.FricLrnSrlComSvcDft -> AvgFricLrn.DefeatFricLearning
    connect CDDInterface.HystCompSrlComSvcDft -> HystComp.DefeatHystService
    connect CDDInterface.IgnCnt -> DiagMgr10.IgnCnt
    connect CDDInterface.IgnCnt -> DiagMgr8.IgnCnt
    connect CDDInterface.IgnCnt -> DiagMgr9.IgnCnt
    connect CDDInterface.LimitSrlComSvcDft -> AstLmt.DefeatLimitService
    connect CDDInterface.LRPRPhaseadvanceCaptured -> DigPhsReasDiag.LRPRPhaseadvanceCaptured
    connect CDDInterface.MeasuredOnTimeA -> DigPhsReasDiag.MeasuredOnTimeA
    connect CDDInterface.MeasuredOnTimeB -> DigPhsReasDiag.MeasuredOnTimeB
    connect CDDInterface.MeasuredOnTimeC -> DigPhsReasDiag.MeasuredOnTimeC
    connect CDDInterface.MEC -> AbsHwPos.ManufMode
    connect CDDInterface.MEC -> AssistFirewall.MEC_Counter
    connect CDDInterface.MEC -> CmMtrCurr.MEC
    connect CDDInterface.MEC -> DampingFirewall.MEC_Counter
    connect CDDInterface.MEC -> DiagMgr10.MEC
    connect CDDInterface.MEC -> DiagMgr8.MEC
    connect CDDInterface.MEC -> DiagMgr9.MEC
    connect CDDInterface.MEC -> DiagSvc.MEC
    connect CDDInterface.MEC -> DigHwTrqSENT.MECCounter
    connect CDDInterface.MEC -> EtDmpFw.MEC_Counter
    connect CDDInterface.MEC -> ReturnFirewall.MEC_Counter
    connect CDDInterface.MEC -> SrlComInput.MEC
    connect CDDInterface.MechMtrPos1 -> VehDyn.MechMtrPos1
    connect CDDInterface.MechMtrPos1TimeStamp -> MtrVel2.MechMtrPos1Timestamp
    connect CDDInterface.MechMtrPos2TimeStamp -> MtrVel.MechMtrPos2Timestamp
    connect CDDInterface.MfgDiagInhibit -> DiagMgr10.MfgDiagInhibit
    connect CDDInterface.MfgDiagInhibit -> DiagMgr8.MfgDiagInhibit
    connect CDDInterface.MfgDiagInhibit -> DiagMgr9.MfgDiagInhibit
    connect CDDInterface.ModIdxFinal -> DigPhsReasDiag.LRPRModulationIndexCaptured
    connect CDDInterface.MtrCurrDax -> ElePwr.MtrCurrDax
    connect CDDInterface.MtrCurrDax -> PeakCurrEst.MtrCurrDax
    connect CDDInterface.MtrCurrK1 -> CmMtrCurr.MtrCurrK1
    connect CDDInterface.MtrCurrK2 -> CmMtrCurr.MtrCurrK2
    connect CDDInterface.MtrCurrQax -> ElePwr.MtrCurrQax
    connect CDDInterface.MtrCurrQax -> PeakCurrEst.MtrCurrQax
    connect CDDInterface.MtrVoltDax -> ElePwr.MtrVoltDax
    connect CDDInterface.MtrVoltQax -> ElePwr.MtrVoltQax
    connect CDDInterface.PullCompSrlComSvcDft -> ActivePull.DisableLearning
    connect CDDInterface.PullCompSrlComSvcDft -> ActivePull.DisableOutput
    connect CDDInterface.ReturnSrlComSvcDft -> Return.DefeatReturnSvc
    connect CDDInterface.ReturnSrlComSvcDft -> ReturnFirewall.Defeat_Return_Svc
    connect CDDInterface.RxMsgsSrlComSvcDft -> SrlComInput.RxMsgsSrlComSvcDft
    connect CDDInterface.RxMtrPosParityAccum -> DigMSB.RxMtrPosParityAccum
    connect CDDInterface.SrlComSvcDft -> CmMtrCurr.SrlComSvcDft
    connect CDDInterface.SysCCorrMtrPosElec -> Gsod.SysC_Corrected_MtrPos
    connect CDDInterface.SysCVSwitchADC -> IoHwAbstractionUsr.SysCVSwitchADC
    connect CDDInterface.ThermalDCSrlComSvcDft -> ThrmlDutyCycle.DefeatDutySvc
    connect CDDInterface.TrqRmpSrlComSvcDft -> StOpCtrl.RampSrlComSvcDft
    connect CDDInterface.UncorrMechMtrPos1 -> DigMSB.UncorrMechMtrPos1
    connect CmMtrCurr.CmMtrCurr_SCom -> NtWrap.C_CmMtrCurr_SCom
    connect CmMtrCurr.ComOffset -> CDDInterface.CommOffset
    connect CmMtrCurr.CurrentGainSvc -> CurrCmd.CurrentGainSvc
    connect CmMtrCurr.MtrCurr1TempOffset -> CDDInterface.MtrCurr1TempOffset
    connect CmMtrCurr.MtrCurr2TempOffset -> CDDInterface.MtrCurr2TempOffset
    connect ComplErr.ComplErr -> AbsHwPos.ComplError
    connect CtrldDisShtdn.CntDisMtrTrqCmdCRF -> AvgFricLrn.CRFMtrTrq
    connect CtrldDisShtdn.CntDisMtrTrqCmdCRF -> ComplErr.TorqueCmdCRF
    connect CtrldDisShtdn.CntDisMtrTrqCmdCRF -> Gsod.Torque_Cmd_CRF
    connect CtrldDisShtdn.CntDisMtrTrqCmdCRF -> VehDyn.TorqueCmdCRF
    connect CtrldDisShtdn.CntDisMtrTrqCmdMRF -> DiagMgr10.MtrTrq
    connect CtrldDisShtdn.CntDisMtrTrqCmdMRF -> DiagMgr8.MtrTrq
    connect CtrldDisShtdn.CntDisMtrTrqCmdMRF -> DiagMgr9.MtrTrq
    connect CtrldDisShtdn.CntDisMtrTrqCmdMRF -> Gsod.Torque_Cmd_MRF
    connect CtrldDisShtdn.CntDisMtrTrqCmdMRF -> PwrLmtFuncCr.CntDisMtrTrqCmdMRF
    connect CtrldDisShtdn.CtrldDmpStsCmp -> ePWM2.CtrldDmpStsCmp
    connect CtrldDisShtdn.CtrldDmpStsCmp -> StaMd.ControlledDampStatusComplete
    connect CtrldDisShtdn.CtrldDmpStsCmp -> StaMd8.ControlledDampStatusComplete
    connect CtrldDisShtdn.SysC_CRFMtrTrqCmd -> Gsod.SysC_Torque_Cmd_CRF
    connect CtrldDisShtdn.SysC_MRFMtrTrqCmd -> Gsod.SysC_Torque_Cmd_MRF
    connect CtrlTemp.FiltMeasTemp -> CmMtrCurr.FiltCntrlTemp
    connect CtrlTemp.FiltMeasTemp -> MtrTempEst.CtrlTempFinal
    connect CtrlTemp.FiltMeasTemp -> ThrmlDutyCycle.FiltMeasTemp
    connect CurrCmd.MtrCurrAngle -> CmMtrCurr.MtrCurrAngle
    connect CurrCmd.MtrCurrDaxRef -> CurrParamComp.MtrCurrDaxRef
    connect CurrCmd.MtrCurrDaxRef -> PICurrCntrl.MtrCurrDaxRef
    connect CurrCmd.MtrCurrDaxRef -> TrqCanc.MtrCurrDaxRef
    connect CurrCmd.MtrCurrQaxRef -> CurrParamComp.MtrCurrQaxRef
    connect CurrCmd.MtrCurrQaxRef -> TrqCanc.MtrCurrQaxRef
    connect CurrCmd.MtrTrqCmdSign -> CDDInterface.MtrTrqCmdSign
    connect CurrParamComp.EstKe -> CurrCmd.EstKe
    connect CurrParamComp.EstKe -> PICurrCntrl.EstKe
    connect CurrParamComp.EstKe -> PwrLmtFuncCr.EstKe
    connect CurrParamComp.EstKe -> TrqCanc.EstKe
    connect CurrParamComp.EstLd -> CurrCmd.EstLd
    connect CurrParamComp.EstLq -> CurrCmd.EstLq
    connect CurrParamComp.EstR -> CurrCmd.EstR
    connect CurrParamComp.EstR -> PICurrCntrl.EstR
    connect CurrParamComp.SCom_EOLNomMtrParam -> NtWrap.C_SCom_EOLNomMtrParam
    connect Damping.DampingCmd -> DampingFirewall.DampingCmd
    connect DampingFirewall.CombinedDamping -> AstLmt.CombinedDamping
    connect DemIf.DemIf -> DiagMgr9.DemIf
    connect DiagMgr10.DiagRampRate -> StOpCtrl.DiagRampRate
    connect DiagMgr10.DiagRampValue -> StOpCtrl.DiagRampValue
    connect DiagMgr10.DiagRmpToZeroActive -> StaMd.FTerm
    connect DiagMgr10.DiagRmpToZeroActive -> StaMd8.FTerm
    connect DiagMgr10.DiagRmpToZeroActive -> StOpCtrl.DiagStsDiagRmpActive
    connect DiagMgr10.DiagStsCtrldDisRmpPres -> CtrldDisShtdn.DiagStsF2Active
    connect DiagMgr10.DiagStsCtrldDisRmpPres -> ePWM2.DiagStsCtrldDisRmpPres
    connect DiagMgr10.DiagStsDefTemp -> CtrlTemp.DiagStsTempRdPrf
    connect DiagMgr10.DiagStsDefVehSpd -> SrlComInput.DefaultVehSpd
    connect DiagMgr10.DiagStsHWASbSystmFltPres -> AbsHwPos.DiagStatusHwPosReducedPerf
    connect DiagMgr10.DiagStsHWASbSystmFltPres -> LrnEOT.DiagStsHwPosDis
    connect DiagMgr10.DiagStsHWASbSystmFltPres -> Return.DiagStsHwPosDis
    connect DiagMgr10.DiagStsNonRecRmpToZeroFltPres -> ePWM2.DiagStsNonRecRmpToZeroFltPres
    connect DiagMgr10.NxtrDiagMgr10 -> AbsHwPos.NxtrDiagMgr
    connect DiagMgr10.NxtrDiagMgr10 -> AssistFirewall.NxtrDiagMgr
    connect DiagMgr10.NxtrDiagMgr10 -> CmMtrCurr.NxtrDiagMgr
    connect DiagMgr10.NxtrDiagMgr10 -> DampingFirewall.NxtrDiagMgr
    connect DiagMgr10.NxtrDiagMgr10 -> DigHwTrqSENT.NxtrDiagMgr
    connect DiagMgr10.NxtrDiagMgr10 -> DigMSB.NxtrDiagMgr
    connect DiagMgr10.NxtrDiagMgr10 -> DigPhsReasDiag.NxtrDiagMgr
    connect DiagMgr10.NxtrDiagMgr10 -> Gsod.NxtrDiagMgr
    connect DiagMgr10.NxtrDiagMgr10 -> IoHwAbstractionUsr.NxtrDiagMgr
    connect DiagMgr10.NxtrDiagMgr10 -> MtrDrvDiag.NxtrDiagMgr
    connect DiagMgr10.NxtrDiagMgr10 -> MtrVel.NxtrDiagMgr
    connect DiagMgr10.NxtrDiagMgr10 -> Nhet1.NxtrDiagMgr
    connect DiagMgr10.NxtrDiagMgr10 -> OvrVoltMon.NxtrDiagMgr
    connect DiagMgr10.NxtrDiagMgr10 -> Polarity.NxtrDiagMgr
    connect DiagMgr10.NxtrDiagMgr10 -> PwrLmtFuncCr.NxtrDiagMgr
    connect DiagMgr10.NxtrDiagMgr10 -> ReturnFirewall.NxtrDiagMgr
    connect DiagMgr10.NxtrDiagMgr10 -> StabilityComp.NxtrDiagMgr
    connect DiagMgr10.NxtrDiagMgr10 -> StaMd.NxtrDiagMgr
    connect DiagMgr10.NxtrDiagMgr10 -> TmprlMon.NxtrDiagMgr
    connect DiagMgr10.NxtrDiagMgr10 -> TqRsDg.NxtrDiagMgr
    connect DiagMgr10.NxtrDiagMgr10 -> uDiag.NxtrDiagMgr
    connect DiagMgr10.NxtrDiagMgr10 -> VehDyn.NxtrDiagMgr
    connect DiagMgr8.NxtrDiagMgr8 -> MtrVel2.NxtrDiagMgr
    connect DiagMgr8.NxtrDiagMgr8 -> StaMd8.NxtrDiagMgr
    connect DiagMgr9.DiagMgr_StaCtrl -> StaMd9.DiagMgr_StaCtrl
    connect DiagMgr9.NxtrDiagMgr9 -> AvgFricLrn.NxtrDiagMgr
    connect DiagMgr9.NxtrDiagMgr9 -> BatteryVoltage.NxtrDiagMgr
    connect DiagMgr9.NxtrDiagMgr9 -> BkCpPc.NxtrDiagMgr
    connect DiagMgr9.NxtrDiagMgr9 -> BVDiag.NxtrDiagMgr
    connect DiagMgr9.NxtrDiagMgr9 -> CtrlTemp.NxtrDiagMgr
    connect DiagMgr9.NxtrDiagMgr9 -> DiagSvc.NxtrDiagMgr
    connect DiagMgr9.NxtrDiagMgr9 -> LrnEOT.NxtrDiagMgr
    connect DiagMgr9.NxtrDiagMgr9 -> SrlComInput.NxtrDiagMgr
    connect DiagMgr9.NxtrDiagMgr9 -> SrlComOutput.NxtrDiagMgr
    connect DiagMgr9.NxtrDiagMgr9 -> ThrmlDutyCycle.NxtrDiagMgr
    connect DiagMgr9.NxtrDiagMgr9 -> VehPwrMd.NxtrDiagMgr
    connect DiagSvc.DesiredTunSet -> ApXcp.DesiredTunSet
    connect DiagSvc.DesiredTunSet -> TuningSelAuth.DesiredTunSet
    connect DigHwTrqSENT.DigHwTrqSENT_SCom -> NtWrap.C_DigHwTrqSENT_SCom
    connect DigHwTrqSENT.HwTorque -> Gsod.Ana_Hw_Torque
    connect DigHwTrqSENT.HwTorque -> Sweep.InputHwTrq
    connect DigHwTrqSENT.SrlComHwTrq -> SrlComOutput.SrlComHwTrq
    connect DigHwTrqSENT.SrlComHwTrqValid -> SrlComOutput.SrlComHwTrqValid
    connect DigHwTrqSENT.SysCHwTorque -> Gsod.SysC_Ana_Hw_Torque
    connect DigMSB.AlignedCumMechMtrPosCRF -> AbsHwPos.AlignedCumMechMtrPosCRF
    connect DigMSB.AlignedCumMechMtrPosStatus -> AbsHwPos.TurnsCntrValidity
    connect DigMSB.CumMechMtrPosCRF -> AbsHwPos.CumMechMtrPosCRF
    connect DigMSB.CumMechMtrPosMRF -> Gsod.Cum_Mtr_Pos_CRF
    connect DigMSB.CumMechMtrPosMRF -> MtrVel2.CumMechMtrPosMRF
    connect DigMSB.CumMechMtrPosMRF -> QuadDet.MRFCumMtrPos
    connect DigMSB.CumMechMtrPosStatus -> SrlComOutput.CumMechMtrPosStatus
    connect DigMSB.MechMtrPos2 -> MtrVel.MechMtrPos2
    connect DigMSB.SysCCumMechMtrPosMRF -> Gsod.SysC_Cum_Mtr_Pos_CRF
    connect ElePwr.SupplyCurrent -> SrlComOutput.SupplyCurrent
    connect EOTActuatorMng.AssistEOTDamping -> EtDmpFw.AssistEOTDamping
    connect EOTActuatorMng.AssistEOTGain -> LmtCod.AssistEOTGain
    connect EOTActuatorMng.AssistEOTLimit -> LmtCod.AssistEOTLimit
    connect EtDmpFw.EOTDampingLtd -> AstLmt.AssistEOTDamping
    connect FltInjection.FltInjection_SCom -> Assist.FltInjection_SCom
    connect FltInjection.FltInjection_SCom -> AvgFricLrn.FltInjection_SCom
    connect FltInjection.FltInjection_SCom -> BatteryVoltage.FltInjection_SCom
    connect FltInjection.FltInjection_SCom -> Damping.FltInjection_SCom
    connect FltInjection.FltInjection_SCom -> DigHwTrqSENT.FaultInjection_SCom
    connect FltInjection.FltInjection_SCom -> EtDmpFw.FaultInjection_SCom
    connect FltInjection.FltInjection_SCom -> FrqDepDmpnInrtCmp.FltInjection_SCom
    connect FltInjection.FltInjection_SCom -> HystComp.FltInjection_SCom
    connect FltInjection.FltInjection_SCom -> LmtCod.FltInjection_SCom
    connect FltInjection.FltInjection_SCom -> Return.FltInjection_SCom
    connect FltInjection.FltInjection_SCom -> SignlCondn.FaultInjection_SCom
    connect FltInjection.FltInjection_SCom -> StabilityComp.FaultInjection_SCom
    connect FrqDepDmpnInrtCmp.FrqDepDmpnInrtCmp -> DampingFirewall.InertiaComp
    connect HaitecTrqCmd.HaitecTrqCmd_SCom -> NtWrap.C_HaitecTrqCmd_SCom
    connect HighFreqAssist.HighFreqAssist -> AssistFirewall.HighFreqAssist
    connect HiLoadStall.AssistStallLimit -> LmtCod.AssistStallLimit
    connect HwPwUp.MtrDrvrInitStart -> MtrDrvDiag.MtrDrvrInitStart
    connect HwPwUp.PwrDiscATestStart -> BkCpPc.PwrDiscATestStart
    connect HwPwUp.PwrDiscBTestStart -> BkCpPc.PwrDiscBTestStart
    connect HwPwUp.PwrDiscBTestStart -> OvrVoltMon.PwrDiscBTestStart
    connect HwPwUp.TMFTestStart -> TmprlMon.TMFTestStart
    connect HystComp.HysteresisComp -> AssistFirewall.HysteresisComp
    connect IoHwAbsDigSig.EpsEn -> SrlComInput.EpsEn
    connect IoHwAbsDigSig.EpsEn -> SrlComOutput.EpsEn
    connect IoHwAbsDigSig.EpsEn -> VehPwrMd.EpsEn
    connect IoHwAbsDigSig.FetDrvCntl -> TmprlMon.FetDrvCntl
    connect IoHwAbsDigSig.FetDrvReset -> MtrDrvDiag.FetDrvReset
    connect IoHwAbsDigSig.FetDrvReset -> ShtdnMech.FetDrvReset
    connect IoHwAbsDigSig.FetFlt1Data -> MtrDrvDiag.FetFlt1Data
    connect IoHwAbsDigSig.FetFlt2Clk -> MtrDrvDiag.FetFlt2Clk
    connect IoHwAbsDigSig.IoHwAbPortConfig -> MtrDrvDiag.IoHwAbPortConfig
    connect IoHwAbsDigSig.OvrVoltFdbk -> OvrVoltMon.phyOvrVoltFdbk
    connect IoHwAbsDigSig.PwrSwitchEn -> TmprlMon.PwrSwitchEn
    connect IoHwAbsDigSig.SysFault2 -> ShtdnMech.SysFault2
    connect IoHwAbsDigSig.SysFault2 -> TmprlMon.SysFault2
    connect IoHwAbsDigSig.SysFault3 -> ShtdnMech.SysFault3
    connect IoHwAbsDigSig.SysFault3 -> TmprlMon.SysFault3
    connect IoHwAbsDigSig.TODReset -> StaMd.TOD
    connect IoHwAbsDigSig.WdMonitor -> TmprlMon.WdMonitor
    connect IoHwAbsDigSig.WdMonitor -> TmprlMon2.WdMonitor
    connect IoHwAbsDigSig.WdReset -> TmprlMon.WdReset
    connect IoHwAbstractionUsr.Batt -> BatteryVoltage.Batt
    connect IoHwAbstractionUsr.Batt -> BkCpPc.Batt
    connect IoHwAbstractionUsr.Batt -> BVDiag.Batt
    connect IoHwAbstractionUsr.Batt -> SrlComInput.Batt
    connect IoHwAbstractionUsr.BattSwitched -> BatteryVoltage.BattSwitched
    connect IoHwAbstractionUsr.BattSwitched -> BkCpPc.BattSwitched
    connect IoHwAbstractionUsr.SysCVSwitch -> BatteryVoltage.SysCVSwitch
    connect IoHwAbstractionUsr.TemperatureADC -> CtrlTemp.TemperatureADC
    connect LmtCod.EOTGainLtd -> AstLmt.AssistEOTGain
    connect LmtCod.EOTLimitLtd -> AstLmt.AssistEOTLimit
    connect LmtCod.OutputRampMultLtd -> AstLmt.OutputRampMult
    connect LmtCod.StallLimitLtd -> AstLmt.AssistStallLimit
    connect LmtCod.ThermalLimitLtd -> AstLmt.ThermalLimit
    connect LmtCod.VehSpdLimitLtd -> AstLmt.AssistVehSpdLimit
    connect LrnEOT.CCWFound -> EOTActuatorMng.CcwFound
    connect LrnEOT.CCWPosition -> EOTActuatorMng.CcwEOT
    connect LrnEOT.CCWPosition -> VehDyn.CcwEOT
    connect LrnEOT.CCWPosition -> VehSpdLmt.CCWPosition
    connect LrnEOT.CWFound -> EOTActuatorMng.CwFound
    connect LrnEOT.CWPosition -> EOTActuatorMng.CwEOT
    connect LrnEOT.CWPosition -> VehDyn.CwEOT
    connect LrnEOT.CWPosition -> VehSpdLmt.CWPosition
    connect LrnEOT.LrnEOT_Scom -> DiagSvc.LrnEOT_Scom
    connect MtrDrvDiag.GateDriveResetActive -> DigPhsReasDiag.GateDriveResetActive
    connect MtrDrvDiag.MtrDrvrInitComplete -> HwPwUp.MtrDrvrInitComplete
    connect MtrTempEst.AssistMechTempEst -> AvgFricLrn.Temperature
    connect MtrTempEst.AssistMechTempEst -> Damping.AssistMechTempEst
    connect MtrTempEst.AssistMechTempEst -> HaitecTrqCmd.AssitMechTempEst
    connect MtrTempEst.AssistMechTempEst -> HystComp.AssistMechTempEst
    connect MtrTempEst.AssistMechTempEst -> Return.AssistMechTempEst
    connect MtrTempEst.CuTempEst -> CurrParamComp.CuTempEst
    connect MtrTempEst.CuTempEst -> ThrmlDutyCycle.CuTempEst
    connect MtrTempEst.MagTempEst -> CurrParamComp.MagTempEst
    connect MtrTempEst.MagTempEst -> ThrmlDutyCycle.MagTempEst
    connect MtrTempEst.SiTempEst -> CurrParamComp.SiTempEst
    connect MtrTempEst.SiTempEst -> ThrmlDutyCycle.SiTempEst
    connect MtrVel.HandwheelVel -> ActivePull.HandwheelVelocity
    connect MtrVel.HandwheelVel -> AvgFricLrn.HwVel
    connect MtrVel.HandwheelVel -> MtrTempEst.HwVel
    connect MtrVel.HandwheelVel -> MtrVel2.HandwheelVel
    connect MtrVel.HandwheelVel -> Return.HandwheelVel
    connect MtrVel.MotorVelCRF -> CtrldDisShtdn.CRFMtrVel
    connect MtrVel.MotorVelCRF -> Damping.MotorVelCRF
    connect MtrVel.MotorVelCRF -> DampingFirewall.MtrVelCRF
    connect MtrVel.MotorVelCRF -> EOTActuatorMng.MotorVel
    connect MtrVel.MotorVelCRF -> EtDmpFw.CRFMtrVel
    connect MtrVel.MotorVelCRF -> FltInjection.MotorVelCRF
    connect MtrVel.MotorVelCRF -> FrqDepDmpnInrtCmp.CRFMotorVel
    connect MtrVel.MotorVelCRF -> HaitecTrqCmd.MtrVelCRF
    connect MtrVel.MotorVelCRF -> HiLoadStall.MtrVelCRF
    connect MtrVel.MotorVelCRF -> LrnEOT.MtrVelCRF
    connect MtrVel.MotorVelCRF -> ThrmlDutyCycle.MotorVelCRF
    connect MtrVel.MotorVelCRF -> VehDyn.MotorVelCRF
    connect MtrVel.MotorVelMRF -> BkCpPc.MotorVelocityMRFUnfiltered
    connect MtrVel.MotorVelMRF -> CDDInterface.MRFMtrVel
    connect MtrVel.MotorVelMRF -> CmMtrCurr.MtrVel
    connect MtrVel.MotorVelMRF -> CurrCmd.MRFMtrVel
    connect MtrVel.MotorVelMRF -> DigPhsReasDiag.MotorVelMRFUnfiltered
    connect MtrVel.MotorVelMRF -> MtrVel2.MotorVelMRF
    connect MtrVel.MotorVelMRF -> PICurrCntrl.MRFMtrVel
    connect MtrVel.MotorVelMRF -> PwrLmtFuncCr.MotorVelMRF
    connect MtrVel.MotorVelMRF -> TrqCanc.MRFMtrVel
    connect MtrVel2.SysCDiagHwVel -> MtrVel.SysCDiagHwVel
    connect MtrVel2.SysCDiagMtrVelMRF -> MtrVel.SysCDiagMtrVelMRF
    connect Nhet1.DigHwTrqT1 -> DigHwTrqSENT.T1
    connect Nhet1.DigHwTrqT2 -> DigHwTrqSENT.T2
    connect NtWrap.AbsHwPos_SCom -> DiagSvc.AbsHwPos_SCom
    connect NtWrap.HaitecTrqCmd_SCom -> DiagSvc.HaitecTrqCmd_SCom
    connect NtWrap.VehDyn_SCom -> DiagSvc.VehDyn_SCom
    connect PeakCurrEst.EstPkCurr -> MtrTempEst.EstPkCurr
    connect PeakCurrEst.EstPkCurr -> ThrmlDutyCycle.MtrPkCurr
    connect PeakCurrEst.FiltEstPkCurr -> ThrmlDutyCycle.FilteredPkCurr
    connect PICurrCntrl.DervLambdaAlphaDiag -> TqRsDg.DervLambdaAlphaDiag
    connect PICurrCntrl.DervLambdaBetaDiag -> TqRsDg.DervLambdaBetaDiag
    connect Polarity.AssistAssyPolarity -> CtrldDisShtdn.AssistAssyPolarity
    connect Polarity.AssistAssyPolarity -> DigMSB.AssistAssemblyPolarity
    connect Polarity.AssistAssyPolarity -> MtrVel.AsstAssemblyPolarity
    connect Polarity.AssistAssyPolarity -> MtrVel2.AsstAssemblyPolarity
    connect Polarity.AssistAssyPolarity -> Polarity.DiagAssistAssyPolarity
    connect Polarity.HwPosPolarity -> Polarity.DiagHwPosPolarity
    connect Polarity.HwTrqPolarity -> Polarity.DiagHwTrqPolarity
    connect Polarity.MtrElecMechPolarity -> CDDInterface.MtrElecMechPolarity
    connect Polarity.MtrElecMechPolarity -> DigPhsReasDiag.MtrElecMechPolarity
    connect Polarity.MtrElecMechPolarity -> Gsod.MtrElecMech_Polarity
    connect Polarity.MtrElecMechPolarity -> Polarity.DiagMtrElecMechPolarity
    connect Polarity.MtrPosPolarity -> CDDInterface.MtrPosPolarity
    connect Polarity.MtrPosPolarity -> DigMSB.MtrPosPolarity
    connect Polarity.MtrPosPolarity -> Polarity.DiagMtrPosPolarity
    connect Polarity.MtrVelPolarity -> Polarity.DiagMtrVelPolarity
    connect Polarity.Polarity_SCom -> NtWrap.C_Polarity_SCom
    connect Polarity.SysC_MtrElecMechPolarity -> Gsod.SysC_MtrElecMech_Polarity
    connect PwrLmtFuncCr.FltTrqLmt -> AstLmt.PowerLimitPerc
    connect PwrLmtFuncCr.MRFMtrTrqCmd -> TrqCmdScl.MRFMtrTrqCmd
    connect QuadDet.MtrQuad -> CurrCmd.MtrQuad
    connect Return.ReturnCmd -> ReturnFirewall.ReturnCmd
    connect ReturnFirewall.LimitedReturn -> AstLmt.LimitedReturn
    connect SignlCondn.VehicleSpeed -> ActivePull.VehicleSpeed
    connect SignlCondn.VehicleSpeed -> Assist.VehSpd
    connect SignlCondn.VehicleSpeed -> AssistFirewall.VehicleSpeed
    connect SignlCondn.VehicleSpeed -> AstLmt.VehSpd
    connect SignlCondn.VehicleSpeed -> AvgFricLrn.VehSpd
    connect SignlCondn.VehicleSpeed -> CmMtrCurr.VehSpd
    connect SignlCondn.VehicleSpeed -> CurrCmd.VehSpd
    connect SignlCondn.VehicleSpeed -> Damping.VehicleSpeed
    connect SignlCondn.VehicleSpeed -> DampingFirewall.VehicleSpeed
    connect SignlCondn.VehicleSpeed -> DiagMgr10.VehSpd
    connect SignlCondn.VehicleSpeed -> DiagMgr8.VehSpd
    connect SignlCondn.VehicleSpeed -> DiagMgr9.VehSpd
    connect SignlCondn.VehicleSpeed -> EOTActuatorMng.VehicleSpeed
    connect SignlCondn.VehicleSpeed -> EtDmpFw.Vehicle_Speed
    connect SignlCondn.VehicleSpeed -> FrqDepDmpnInrtCmp.VehicleSpeed
    connect SignlCondn.VehicleSpeed -> HaitecTrqCmd.VehSpd
    connect SignlCondn.VehicleSpeed -> HighFreqAssist.VehicleSpeed
    connect SignlCondn.VehicleSpeed -> HystComp.VehicleSpeed
    connect SignlCondn.VehicleSpeed -> LmtCod.VehicleSpeed
    connect SignlCondn.VehicleSpeed -> Return.VehicleSpeed
    connect SignlCondn.VehicleSpeed -> ReturnFirewall.VehicleSpeed
    connect SignlCondn.VehicleSpeed -> StabilityComp.VehicleSpeed
    connect SignlCondn.VehicleSpeed -> StabilityComp2.VehicleSpeed
    connect SignlCondn.VehicleSpeed -> Sweep.VehSpd
    connect SignlCondn.VehicleSpeed -> TuningSelAuth.VehicleSpeed
    connect SignlCondn.VehicleSpeed -> VehDyn.VehicleSpeed
    connect SignlCondn.VehicleSpeed -> VehSpdLmt.VehSpd
    connect SrlComInput.EngineSpeed -> VehPwrMd.EngineSpeed
    connect SrlComInput.EngineSpeedValid -> VehPwrMd.EngineSpeedValid
    connect SrlComInput.SrlComVehSpd -> SignlCondn.SrlComVehSpeed
    connect SrlComInput.SrlComVehSpd -> VehPwrMd.VehicleSpeed
    connect SrlComInput.VehicleSpeedValid -> ActivePull.VehicleSpeedValid
    connect SrlComInput.VehicleSpeedValid -> AvgFricLrn.VehicleSpeedValid
    connect SrlComInput.VehicleSpeedValid -> CmMtrCurr.VhSpdValid
    connect SrlComInput.VehicleSpeedValid -> Sweep.VehSpdValid
    connect SrlComInput.VehicleSpeedValid -> VehDyn.VehicleSpeedValid
    connect SrlComInput.VehicleSpeedValid -> VehPwrMd.VehicleSpeedValid
    connect StabilityComp.AssistCmd -> AstLmt.AssistCmd
    connect StabilityComp.AssistCmd -> Damping.AssistCmd
    connect StabilityComp2.SysAssistCmd -> StabilityComp.SysAssistCmd_MtrNm
    connect StaMd.MilestoneRqst -> HwPwUp.MilestoneRqst
    connect StaMd.SystemState -> CDDInterface.SystemState
    connect StaMd.SystemState -> CmMtrCurr.SystemState
    connect StaMd.SystemState -> CtrldDisShtdn.SystemState
    connect StaMd.SystemState -> DiagMgr10.SystemState
    connect StaMd.SystemState -> DigPhsReasDiag.SystemState
    connect StaMd.SystemState -> ePWM2.SystemState
    connect StaMd.SystemState -> FrqDepDmpnInrtCmp.SystemState
    connect StaMd.SystemState -> Gsod.SystemState
    connect StaMd.SystemState -> HwPwUp.SystemState
    connect StaMd.SystemState -> MtrDrvDiag.SystemState
    connect StaMd.SystemState -> OvrVoltMon.SystemState
    connect StaMd.SystemState -> PeakCurrEst.SystemState
    connect StaMd.SystemState -> PICurrCntrl.SystemState
    connect StaMd.SystemState -> PwrLmtFuncCr.SystemState
    connect StaMd.SystemState -> RteErrata.SystemState
    connect StaMd.SystemState -> StaMd.CurrentSystemState
    connect StaMd.SystemState -> TmprlMon.SystemState
    connect StaMd.SystemState -> TqRsDg.SystemState
    connect StaMd.SystemState -> VehDyn.SystemState
    connect StaMd8.SystemState8 -> DiagMgr8.SystemState
    connect StaMd8.SystemState8 -> RteErrata8.SystemState
    connect StaMd9.StaMd_SCom -> DiagSvc.StaMd_SCom
    connect StaMd9.SystemState9 -> ActivePull.SystemState
    connect StaMd9.SystemState9 -> AvgFricLrn.SystemState
    connect StaMd9.SystemState9 -> BatteryVoltage.SystemState
    connect StaMd9.SystemState9 -> BkCpPc.SystemState
    connect StaMd9.SystemState9 -> DiagMgr9.SystemState
    connect StaMd9.SystemState9 -> DiagSvc.SystemState
    connect StaMd9.SystemState9 -> RteErrata9.SystemState
    connect StaMd9.SystemState9 -> SrlComInput.SystemState
    connect StaMd9.SystemState9 -> SrlComOutput.SystemState
    connect StOpCtrl.OutputRampMult -> LmtCod.OutputRampMult
    connect StOpCtrl.OutputRampMult -> TqRsDg.OutputRampMult
    connect StOpCtrl.RampDwnStatusComplete -> ePWM2.RampDwnStatusComplete
    connect StOpCtrl.RampDwnStatusComplete -> StaMd.RampStatusComplete
    connect StOpCtrl.RampDwnStatusComplete -> StaMd8.RampStatusComplete
    connect Sweep.OutputHwTrq -> ActivePull.HwTorque
    connect Sweep.OutputHwTrq -> Assist.HwTrq
    connect Sweep.OutputHwTrq -> AssistFirewall.HwTorque
    connect Sweep.OutputHwTrq -> AvgFricLrn.HwTrq
    connect Sweep.OutputHwTrq -> Damping.HwTorque
    connect Sweep.OutputHwTrq -> DampingFirewall.HwTorque
    connect Sweep.OutputHwTrq -> DiagMgr10.HwTrq
    connect Sweep.OutputHwTrq -> DiagMgr8.HwTrq
    connect Sweep.OutputHwTrq -> DiagMgr9.HwTrq
    connect Sweep.OutputHwTrq -> EOTActuatorMng.HwTorque
    connect Sweep.OutputHwTrq -> FrqDepDmpnInrtCmp.HwTorque
    connect Sweep.OutputHwTrq -> HaitecTrqCmd.HwTrq
    connect Sweep.OutputHwTrq -> HighFreqAssist.HwTorque
    connect Sweep.OutputHwTrq -> HystComp.HwTorque
    connect Sweep.OutputHwTrq -> LrnEOT.HwTorque
    connect Sweep.OutputHwTrq -> Return.HwTorque
    connect Sweep.OutputHwTrq -> StabilityComp.HwTorque
    connect Sweep.OutputHwTrq -> StabilityComp2.HwTorque
    connect Sweep.OutputHwTrq -> TuningSelAuth.HwTorque
    connect Sweep.OutputHwTrq -> VehDyn.HwTorque
    connect Sweep2.OutputMtrTrq -> CtrldDisShtdn.SumLimTrqCmd
    connect ThrmlDutyCycle.DutyCycleLevel -> Assist.DutyCycleLevel
    connect ThrmlDutyCycle.ThermalLimit -> LmtCod.ThermalLimit
    connect ThrmlDutyCycle.ThermLimitPerc -> AstLmt.ThermalLimitPerc
    connect TmprlMon.TMFTestComplete -> HwPwUp.TMFTestComplete
    connect TmprlMon.TMFTestComplete -> StaMd.TMFTestComplete
    connect TmprlMon.TMFTestComplete -> StaMd8.TMFTestComplete
    connect TrqCanc.TrqCanc_Scom -> NtWrap.C_TrqCanc_Scom
    connect TrqCmdScl.MRFMtrTrqCmdScl -> CurrCmd.MRFTrqCmdScl
    connect TrqCmdScl.MRFMtrTrqCmdScl -> QuadDet.MRFMtrTrqCmdScl
    connect TrqCmdScl.TrqCmdScl_SCom -> NtWrap.C_TrqCmdScl_SCom
    connect TuningSelAuth.ActiveTunPers -> ApXcp.ActiveTunPers
    connect TuningSelAuth.ActiveTunSet -> ApXcp.ActiveTunSet
    connect VehDyn.SensorlessAuthority -> AbsHwPos.SensorlessAuthority
    connect VehDyn.SensorlessHwPos -> AbsHwPos.SensorlessHwPos
    connect VehDyn.VehDyn_SCom -> NtWrap.C_VehDyn_SCom
    connect VehPwrMd.ATermActive -> StaMd.ATerm
    connect VehPwrMd.ATermActive -> StaMd8.ATerm
    connect VehPwrMd.CTermActive -> StaMd.CTerm
    connect VehPwrMd.CTermActive -> StaMd8.CTerm
    connect VehPwrMd.OperRampRate -> StOpCtrl.OperRampRate
    connect VehPwrMd.OperRampValue -> StOpCtrl.OperRampValue
    connect VehSpdLmt.AstVehSpdLimit -> LmtCod.AssistVehSpdLimit
    delegate SrlComInput.Com_BCM_Key_Sta <-> outer port Com_BCM_Key_Sta
    delegate SrlComInput.Com_CAN_N <-> outer port Com_CAN_N
    delegate SrlComInput.Com_LV_CAN_N_ERR <-> outer port Com_LV_CAN_N_ERR
    delegate SrlComInput.Com_VehSpeed <-> outer port Com_VehSpeed
    delegate SrlComOutput.Com_Elect_PWR_Consumpt <-> outer port Com_Elect_PWR_Consumpt
    delegate SrlComOutput.Com_EpasFailed <-> outer port Com_EpasFailed
    delegate SrlComOutput.Com_Rel_Steer_Wheel_Ang <-> outer port Com_Rel_Steer_Wheel_Ang
    delegate SrlComOutput.Com_Rel_Steer_Wheel_Ang_Validity <-> outer port Com_Rel_Steer_Wheel_Ang_Validity
    delegate SrlComOutput.Com_SAS_Angle <-> outer port Com_SAS_Angle
    delegate SrlComOutput.Com_SAS_CAL <-> outer port Com_SAS_CAL
    delegate SrlComOutput.Com_SAS_CheckSum <-> outer port Com_SAS_CheckSum
    delegate SrlComOutput.Com_SAS_Init <-> outer port Com_SAS_Init
    delegate SrlComOutput.Com_SAS_MsgCount <-> outer port Com_SAS_MsgCount
    delegate SrlComOutput.Com_SAS_OK <-> outer port Com_SAS_OK
    delegate SrlComOutput.Com_Steering_Torque <-> outer port Com_Steering_Torque
    delegate SrlComOutput.Com_Steering_Torque_V <-> outer port Com_Steering_Torque_V
package /VehicleProject
  system EPS: fibex-element=[CAN00, DCM_DiagFuncReqFT_Tp__CAN00, EPS, ABS2__CAN00, BCM1__CAN00, DiagFuncReqFT__CAN00, DiagPhysReqToEPAS__CAN00, DiagRespFromEPAS__CAN00, ECM1__CAN00, EPAS1__CAN00, EPAS2__CAN00, GliwaMaster__CAN00, GliwaSlave__CAN00, NMmBCM__CAN00, NMmEPAS__CAN00, XcpMaster__CAN00, XcpSlave__CAN00, BCM_Key_Sta_BCM1__CAN00, CAN_N_ECM1__CAN00, Elect_PWR_Consumpt_EPAS2__CAN00, EpasFailed_EPAS2__CAN00, LV_CAN_N_ERR_ECM1__CAN00, Rel_Steer_Wheel_Ang_EPAS2__CAN00, Rel_Steer_Wheel_Ang_Validity_EPAS2__CAN00, SAS_Angle_EPAS1__CAN00, SAS_CAL_EPAS1__CAN00, SAS_CheckSum_EPAS1__CAN00, SAS_Init_EPAS1__CAN00, SAS_MsgCount_EPAS1__CAN00, SAS_OK_EPAS1__CAN00, Steering_Torque_EPAS2__CAN00, Steering_Torque_V_EPAS2__CAN00, VehSpeed_ABS2__CAN00, DiagFuncReqFT_Tp__CAN00, DiagPhysReqToEPAS_Tp__CAN00, DiagRespFromEPAS_Tp__CAN00, GliwaMaster__CAN00, GliwaSlave__CAN00, NMmBCM__CAN00, NMmEPAS__CAN00, XcpMaster__CAN00, XcpSlave__CAN00, ABS2__CAN00, BCM1__CAN00, ECM1__CAN00, EPAS1__CAN00, EPAS2__CAN00]
    mapping EPS_MPPNG
      data-mappings:
        data-element=ECU_Composition.Com_BCM_Key_Sta.Cnt_enum, signal=BCM_Key_Sta
        data-element=ECU_Composition.Com_CAN_N.Cnt_u16, signal=CAN_N
        data-element=ECU_Composition.Com_Elect_PWR_Consumpt.Cnt_u08, signal=Elect_PWR_Consumpt
        data-element=ECU_Composition.Com_EpasFailed.Cnt_lgc, signal=EpasFailed
        data-element=ECU_Composition.Com_LV_CAN_N_ERR.Cnt_lgc, signal=LV_CAN_N_ERR
        data-element=ECU_Composition.Com_Rel_Steer_Wheel_Ang.Cnt_u16, signal=Rel_Steer_Wheel_Ang
        data-element=ECU_Composition.Com_Rel_Steer_Wheel_Ang_Validity.Cnt_lgc, signal=Rel_Steer_Wheel_Ang_Validity
        data-element=ECU_Composition.Com_SAS_Angle.Cnt_u16, signal=SAS_Angle
        data-element=ECU_Composition.Com_SAS_CAL.Cnt_lgc, signal=SAS_CAL
        data-element=ECU_Composition.Com_SAS_CheckSum.Cnt_u08, signal=SAS_CheckSum
        data-element=ECU_Composition.Com_SAS_Init.Cnt_lgc, signal=SAS_Init
        data-element=ECU_Composition.Com_SAS_MsgCount.Cnt_u08, signal=SAS_MsgCount
        data-element=ECU_Composition.Com_SAS_OK.Cnt_lgc, signal=SAS_OK
        data-element=ECU_Composition.Com_Steering_Torque.Cnt_u08, signal=Steering_Torque
        data-element=ECU_Composition.Com_Steering_Torque_V.Cnt_lgc, signal=Steering_Torque_V
        data-element=ECU_Composition.Com_VehSpeed.Cnt_u16, signal=VehSpeed
        data-element=ECU_Composition.SrlComInput.Com_BCM_Key_Sta.Cnt_enum, signal=BCM_Key_Sta
        data-element=ECU_Composition.SrlComInput.Com_CAN_N.Cnt_u16, signal=CAN_N
        data-element=ECU_Composition.SrlComInput.Com_LV_CAN_N_ERR.Cnt_lgc, signal=LV_CAN_N_ERR
        data-element=ECU_Composition.SrlComInput.Com_VehSpeed.Cnt_u16, signal=VehSpeed
        data-element=ECU_Composition.SrlComOutput.Com_Elect_PWR_Consumpt.Cnt_u08, signal=Elect_PWR_Consumpt
        data-element=ECU_Composition.SrlComOutput.Com_EpasFailed.Cnt_lgc, signal=EpasFailed
        data-element=ECU_Composition.SrlComOutput.Com_Rel_Steer_Wheel_Ang.Cnt_u16, signal=Rel_Steer_Wheel_Ang
        data-element=ECU_Composition.SrlComOutput.Com_Rel_Steer_Wheel_Ang_Validity.Cnt_lgc, signal=Rel_Steer_Wheel_Ang_Validity
        data-element=ECU_Composition.SrlComOutput.Com_SAS_Angle.Cnt_u16, signal=SAS_Angle
        data-element=ECU_Composition.SrlComOutput.Com_SAS_CAL.Cnt_lgc, signal=SAS_CAL
        data-element=ECU_Composition.SrlComOutput.Com_SAS_CheckSum.Cnt_u08, signal=SAS_CheckSum
        data-element=ECU_Composition.SrlComOutput.Com_SAS_Init.Cnt_lgc, signal=SAS_Init
        data-element=ECU_Composition.SrlComOutput.Com_SAS_MsgCount.Cnt_u08, signal=SAS_MsgCount
        data-element=ECU_Composition.SrlComOutput.Com_SAS_OK.Cnt_lgc, signal=SAS_OK
        data-element=ECU_Composition.SrlComOutput.Com_Steering_Torque.Cnt_u08, signal=Steering_Torque
        data-element=ECU_Composition.SrlComOutput.Com_Steering_Torque_V.Cnt_lgc, signal=Steering_Torque_V
      sw-impl-mappings:
        87 x swc to impl mapping:
          D_32069859_727D_47AA_8B9B_ADF4DFF89E9F_IMPL: component-implementation=Ap_AbsHwPos_Implementation, component=ECU_Composition.AbsHwPos
          D_462681EB_DF79_423C_A370_070D2B070792_IMPL: component-implementation=Ap_ActivePull_Implementation, component=ECU_Composition.ActivePull
          D_3ADA3DD1_774A_4C0E_96AC_1CD3B0718322_IMPL: component-implementation=Ap_ApXcp_Implementation, component=ECU_Composition.ApXcp
          D_35E1D41C_D056_4876_8617_3E65448F2D89_IMPL: component-implementation=Ap_Assist_Implementation, component=ECU_Composition.Assist
          D_F10E4667_6E1E_4109_9982_A2764AA60FD2_IMPL: component-implementation=Ap_AssistFirewall_Implementation, component=ECU_Composition.AssistFirewall
          D_9B552ACB_EC61_4241_8925_B60D79F0F719_IMPL: component-implementation=Ap_AstLmt_Implementation, component=ECU_Composition.AstLmt
          D_B82E33BA_194A_44D0_A8CF_F105C6422247_IMPL: component-implementation=Ap_AvgFricLrn_Implementation, component=ECU_Composition.AvgFricLrn
          D_5E8F3494_77CA_4793_9AC0_B5BF8357A8FB_IMPL: component-implementation=Ap_BatteryVoltage_Implementation, component=ECU_Composition.BatteryVoltage
          D_7633AF87_1F64_4CCB_9115_A3C7FFAEF64E_IMPL: component-implementation=Sa_BkCpPc_Implementation, component=ECU_Composition.BkCpPc
          D_CCC970B0_AA95_4EFE_A1DF_2CB9B64D2DC3_IMPL: component-implementation=Ap_BVDiag_Implementation, component=ECU_Composition.BVDiag
          D_0A9D289F_5332_4CED_989D_2C4F91054587_IMPL: component-implementation=Sa_CDDInterface_Implementation, component=ECU_Composition.CDDInterface
          D_FA796A59_509C_42CE_939D_0D44E8FB3162_IMPL: component-implementation=Ap_ChkPtAp10_Implementation, component=ECU_Composition.ChkPtAp10
          D_DD6CDE67_E746_4FA7_89B3_10E6CBAA3660_IMPL: component-implementation=Ap_ChkPtAp8_Implementation, component=ECU_Composition.ChkPtAp8
          D_8CEFF0D1_9C86_460E_9CB4_B55F6B39C48C_IMPL: component-implementation=Ap_ChkPtAp9_Implementation, component=ECU_Composition.ChkPtAp9
          D_0CBF69A9_788E_4F4A_9CCC_95C6DC46B668_IMPL: component-implementation=Sa_CmMtrCurr_Implementation, component=ECU_Composition.CmMtrCurr
          D_B99A7882_4636_4828_8371_14E26CD6D87C_IMPL: component-implementation=Ap_ComplErr_Implementation, component=ECU_Composition.ComplErr
          D_BF2D3A85_2853_4CA9_A187_05D7AF268433_IMPL: component-implementation=Ap_CtrldDisShtdn_Implementation, component=ECU_Composition.CtrldDisShtdn
          D_793C643E_057A_481A_829E_72882F46ED33_IMPL: component-implementation=Sa_CtrlTemp_Implementation, component=ECU_Composition.CtrlTemp
          D_8F9EDAE2_7273_406B_BD77_A319D8F1AEAD_IMPL: component-implementation=Ap_CurrCmd_Implementation, component=ECU_Composition.CurrCmd
          D_16715DB1_E435_4651_8998_2F9B941B9BDA_IMPL: component-implementation=Ap_CurrParamComp_Implementation, component=ECU_Composition.CurrParamComp
          D_F0F0ABED_5577_4F88_AE5F_842FCA797B32_IMPL: component-implementation=Ap_Damping_Implementation, component=ECU_Composition.Damping
          D_A6B383F7_B581_4F28_BA55_B7062A0A9379_IMPL: component-implementation=Ap_DampingFirewall_Implementation, component=ECU_Composition.DampingFirewall
          D_3DFF91E1_7AFC_4153_A404_8AC3E37DD734_IMPL: component-implementation=Ap_DemIf_Implementation, component=ECU_Composition.DemIf
          D_BFF2A07B_3090_4296_ABF2_D1591FE8CAF0_IMPL: component-implementation=Ap_DiagMgr10_Implementation, component=ECU_Composition.DiagMgr10
          D_B5CF7906_39B9_4691_B0F2_802F488D711B_IMPL: component-implementation=Ap_DiagMgr8_Implementation, component=ECU_Composition.DiagMgr8
          D_53B9067B_BDCD_49D3_B8C1_3DCCF2EF9039_IMPL: component-implementation=Ap_DiagMgr9_Implementation, component=ECU_Composition.DiagMgr9
          D_FAE52953_44D4_4261_959C_24A5F6BA8FF9_IMPL: component-implementation=Ap_DiagSvc_Implementation, component=ECU_Composition.DiagSvc
          D_B977BC88_5669_49AE_974B_4A290725D421_IMPL: component-implementation=Sa_DigHwTrqSENT_Implementation, component=ECU_Composition.DigHwTrqSENT
          D_600B313C_A37C_4528_9C3C_BD9B1230BA69_IMPL: component-implementation=Sa_DigMSB_Implementation, component=ECU_Composition.DigMSB
          D_B56C0208_C9A1_4CF2_BD8F_713E67AAD78C_IMPL: component-implementation=Ap_DigPhsReasDiag_Implementation, component=ECU_Composition.DigPhsReasDiag
          D_7F8F9969_60A3_438C_87EE_212608D785D9_IMPL: component-implementation=Ap_ElePwr_Implementation, component=ECU_Composition.ElePwr
          D_9D667EDD_BFAC_4F4B_8104_CF061BE42C92_IMPL: component-implementation=Ap_EOTActuatorMng_Implementation, component=ECU_Composition.EOTActuatorMng
          D_471ACE2F_424B_4C85_A67C_00529EA8FC9C_IMPL: component-implementation=Ap_ePWM2_Implementation, component=ECU_Composition.ePWM2
          D_2C1CAF89_1C7A_4B73_97A8_B67A947D1AF7_IMPL: component-implementation=Ap_EtDmpFw_Implementation, component=ECU_Composition.EtDmpFw
          D_620645F1_2670_4593_9220_220EF30F61FC_IMPL: component-implementation=Ap_FltInjection_Implementation, component=ECU_Composition.FltInjection
          D_371BA6CE_0492_43F7_B577_C0CF59D6B190_IMPL: component-implementation=Ap_FrqDepDmpnInrtCmp_Implementation, component=ECU_Composition.FrqDepDmpnInrtCmp
          D_4ED53FF9_8833_4A47_B28F_9A2E9A253C30_IMPL: component-implementation=Ap_Gsod_Implementation, component=ECU_Composition.Gsod
          D_BA0F4F63_EAF7_49D1_A538_D859A6C05FBA_IMPL: component-implementation=Ap_HaitecTrqCmd_Implementation, component=ECU_Composition.HaitecTrqCmd
          D_159340D1_ED1D_4388_B5FE_8A0565E9972E_IMPL: component-implementation=Ap_HighFreqAssist_Implementation, component=ECU_Composition.HighFreqAssist
          D_A4FF533A_7AF8_46A3_BB8B_BF583DC7BE64_IMPL: component-implementation=Ap_HiLoadStall_Implementation, component=ECU_Composition.HiLoadStall
          D_3F60E6F1_2AF9_4EA9_B353_E96D1057D619_IMPL: component-implementation=Ap_HwPwUp_Implementation, component=ECU_Composition.HwPwUp
          D_723CF942_CAAC_4671_9C2C_FA9BDF92345D_IMPL: component-implementation=Ap_HystComp_Implementation, component=ECU_Composition.HystComp
          D_301B1A35_4DE1_417B_9D57_9EE99B8B750C_IMPL: component-implementation=IoHwAbstraction_Implementation, component=ECU_Composition.IoHwAbsDigSig
          D_F0E25EE8_3FC6_4F1C_BAEE_9006415633E3_IMPL: component-implementation=IoHwAbstractionUsr_Implementation, component=ECU_Composition.IoHwAbstractionUsr
          D_782B12F8_330C_49A0_96C1_01467D1AD3DF_IMPL: component-implementation=Ap_LmtCod_Implementation, component=ECU_Composition.LmtCod
          D_617B25E4_AF0E_4704_86D1_0E6687DABE7A_IMPL: component-implementation=Ap_LrnEOT_Implementation, component=ECU_Composition.LrnEOT
          D_367D54C9_49A1_484F_A649_074E22429BE3_IMPL: component-implementation=Sa_MtrDrvDiag_Implementation, component=ECU_Composition.MtrDrvDiag
          D_FBCF84B2_A569_4A58_BDF8_50A921098FE9_IMPL: component-implementation=Ap_MtrTempEst_Implementation, component=ECU_Composition.MtrTempEst
          D_E6BE401B_E46E_4B25_ACE7_E32961603E5B_IMPL: component-implementation=Sa_MtrVel_Implementation, component=ECU_Composition.MtrVel
          D_C5357F49_762A_489F_A7F3_66CCA9BF6F46_IMPL: component-implementation=Sa_MtrVel2_Implementation, component=ECU_Composition.MtrVel2
          D_102CC892_6FA5_4678_8A40_23A731313F3B_IMPL: component-implementation=Sa_MtrVel3_Implementation, component=ECU_Composition.MtrVel3
          D_A7834DC8_520F_4FD2_9619_E4333A3A0F49_IMPL: component-implementation=Cd_Nhet1_Implementation, component=ECU_Composition.Nhet1
          D_0F5E361A_405A_425C_AF8F_3DD442C0139D_IMPL: component-implementation=NtWrap_Implementation, component=ECU_Composition.NtWrap
          D_6C14E912_513D_497C_8D06_0685B2C3FA90_IMPL: component-implementation=Sa_OvrVoltMon_Implementation, component=ECU_Composition.OvrVoltMon
          D_A55A9D90_CC2D_44B2_B55D_54C3F39527B1_IMPL: component-implementation=Ap_PeakCurrEst_Implementation, component=ECU_Composition.PeakCurrEst
          D_C8D0D855_F67A_4D1F_8673_B30AA9EAB927_IMPL: component-implementation=Ap_PICurrCntrl_Implementation, component=ECU_Composition.PICurrCntrl
          D_0A1AFEAB_DA3C_4A6D_BC3D_2EB7036CAB45_IMPL: component-implementation=Ap_Polarity_Implementation, component=ECU_Composition.Polarity
          D_C6F97FAC_5A5A_41A9_8565_79D48DE92A51_IMPL: component-implementation=Ap_PwrLmtFuncCr_Implementation, component=ECU_Composition.PwrLmtFuncCr
          D_D3B70E67_12D8_408B_913E_AB86B4F924FC_IMPL: component-implementation=Ap_QuadDet_Implementation, component=ECU_Composition.QuadDet
          D_5D0E306F_6110_439C_BD7D_41899168F591_IMPL: component-implementation=Ap_Return_Implementation, component=ECU_Composition.Return
          D_E368FBEF_03FC_485D_90A6_DCDEAB3DF918_IMPL: component-implementation=Ap_ReturnFirewall_Implementation, component=ECU_Composition.ReturnFirewall
          D_4A2BEFA2_EE0E_4288_B799_CED4380D5412_IMPL: component-implementation=RteErrata10_Implementation, component=ECU_Composition.RteErrata
          D_3E6837B7_9FE2_4197_B696_EADB779B762B_IMPL: component-implementation=RteErrata8_Implementation, component=ECU_Composition.RteErrata8
          D_86A80C5D_A1A9_4312_BD42_E55D3E05720B_IMPL: component-implementation=RteErrata9_Implementation, component=ECU_Composition.RteErrata9
          D_23E033FB_78C4_4E5D_981F_61652454C2B6_IMPL: component-implementation=Sa_ShtdnMech_Implementation, component=ECU_Composition.ShtdnMech
          D_26E47738_5578_4959_A9EF_A920E9B259D5_IMPL: component-implementation=Ap_SignlCondn_Implementation, component=ECU_Composition.SignlCondn
          D_86F6AB25_832B_4395_AE65_21B517EE3694_IMPL: component-implementation=Ap_SrlComInput_Implementation, component=ECU_Composition.SrlComInput
          D_2C16A642_37DA_4723_B180_1B5C7B9A59DD_IMPL: component-implementation=Ap_SrlComOutput_Implementation, component=ECU_Composition.SrlComOutput
          D_6F370927_6B4C_4268_BDEC_FC8D1671EF04_IMPL: component-implementation=Ap_StabilityComp_Implementation, component=ECU_Composition.StabilityComp
          D_48092368_C0CE_4103_9685_C5CD38781A59_IMPL: component-implementation=Ap_StabilityComp2_Implementation, component=ECU_Composition.StabilityComp2
          D_740243BD_F900_4EEE_8B19_C2F3D439C269_IMPL: component-implementation=Ap_StaMd_Implementation, component=ECU_Composition.StaMd
          D_ACB007BC_251D_4BE6_AE86_364A6BCA67B3_IMPL: component-implementation=Ap_StaMd8_Implementation, component=ECU_Composition.StaMd8
          D_20B320B6_DD0F_471F_A3A9_C9689EA7DEF1_IMPL: component-implementation=Ap_StaMd9_Implementation, component=ECU_Composition.StaMd9
          D_0B3A265F_7BDF_43D6_AEA3_6704B83120D2_IMPL: component-implementation=Ap_StOpCtrl_Implementation, component=ECU_Composition.StOpCtrl
          D_5D5F0B52_F7F6_4D74_AAFA_98961CCE63B3_IMPL: component-implementation=Ap_Sweep_Implementation, component=ECU_Composition.Sweep
          D_EE2384FA_2E65_4698_AC68_C3D0E7374B1D_IMPL: component-implementation=Ap_Sweep2_Implementation, component=ECU_Composition.Sweep2
          D_F68E7F06_7CBD_4682_A9FD_43F8C4D5C6CB_IMPL: component-implementation=Ap_ThrmlDutyCycle_Implementation, component=ECU_Composition.ThrmlDutyCycle
          D_6257C789_8231_43EA_8768_1B2E185C872A_IMPL: component-implementation=Sa_TmprlMon_Implementation, component=ECU_Composition.TmprlMon
          D_A76F58E1_0218_4D66_AD1D_EDDEDFE8CAB3_IMPL: component-implementation=Sa_TmprlMon2_Implementation, component=ECU_Composition.TmprlMon2
          D_109D320F_6F29_42C0_9CE0_C864AEC15BC3_IMPL: component-implementation=Ap_TqRsDg_Implementation, component=ECU_Composition.TqRsDg
          D_767A76B3_914B_4C30_8A34_07FDC1772D80_IMPL: component-implementation=Ap_TrqCanc_Implementation, component=ECU_Composition.TrqCanc
          D_EB57F99E_B02F_48AF_A1C1_7827F6490E9F_IMPL: component-implementation=Ap_TrqCmdScl_Implementation, component=ECU_Composition.TrqCmdScl
          D_574EEB98_F0BF_4B29_9B1F_FAB98468FB07_IMPL: component-implementation=Ap_TuningSelAuth_Implementation, component=ECU_Composition.TuningSelAuth
          D_C494D763_5DE0_4CCE_B057_DF89DAF2DE60_IMPL: component-implementation=Cd_uDiag_Implementation, component=ECU_Composition.uDiag
          D_5515B0B4_6D7E_4377_B1FB_80BC4233E981_IMPL: component-implementation=Ap_VehDyn_Implementation, component=ECU_Composition.VehDyn
          D_AE230A9D_0217_4A33_A7A3_F3C2DE497C16_IMPL: component-implementation=Ap_VehPwrMd_Implementation, component=ECU_Composition.VehPwrMd
          D_C9B4F0C1_8CED_40A8_9F32_C1C114FDDA55_IMPL: component-implementation=Ap_VehSpdLmt_Implementation, component=ECU_Composition.VehSpdLmt
      sw-mappings:
        87 x swc to ecu mapping, all with ecu-instance=EPS:
          D_32069859_727D_47AA_8B9B_ADF4DFF89E9F_: component=ECU_Composition.AbsHwPos
          D_462681EB_DF79_423C_A370_070D2B070792_: component=ECU_Composition.ActivePull
          D_3ADA3DD1_774A_4C0E_96AC_1CD3B0718322_: component=ECU_Composition.ApXcp
          D_35E1D41C_D056_4876_8617_3E65448F2D89_: component=ECU_Composition.Assist
          D_F10E4667_6E1E_4109_9982_A2764AA60FD2_: component=ECU_Composition.AssistFirewall
          D_9B552ACB_EC61_4241_8925_B60D79F0F719_: component=ECU_Composition.AstLmt
          D_B82E33BA_194A_44D0_A8CF_F105C6422247_: component=ECU_Composition.AvgFricLrn
          D_5E8F3494_77CA_4793_9AC0_B5BF8357A8FB_: component=ECU_Composition.BatteryVoltage
          D_7633AF87_1F64_4CCB_9115_A3C7FFAEF64E_: component=ECU_Composition.BkCpPc
          D_CCC970B0_AA95_4EFE_A1DF_2CB9B64D2DC3_: component=ECU_Composition.BVDiag
          D_0A9D289F_5332_4CED_989D_2C4F91054587_: component=ECU_Composition.CDDInterface
          D_FA796A59_509C_42CE_939D_0D44E8FB3162_: component=ECU_Composition.ChkPtAp10
          D_DD6CDE67_E746_4FA7_89B3_10E6CBAA3660_: component=ECU_Composition.ChkPtAp8
          D_8CEFF0D1_9C86_460E_9CB4_B55F6B39C48C_: component=ECU_Composition.ChkPtAp9
          D_0CBF69A9_788E_4F4A_9CCC_95C6DC46B668_: component=ECU_Composition.CmMtrCurr
          D_B99A7882_4636_4828_8371_14E26CD6D87C_: component=ECU_Composition.ComplErr
          D_BF2D3A85_2853_4CA9_A187_05D7AF268433_: component=ECU_Composition.CtrldDisShtdn
          D_793C643E_057A_481A_829E_72882F46ED33_: component=ECU_Composition.CtrlTemp
          D_8F9EDAE2_7273_406B_BD77_A319D8F1AEAD_: component=ECU_Composition.CurrCmd
          D_16715DB1_E435_4651_8998_2F9B941B9BDA_: component=ECU_Composition.CurrParamComp
          D_F0F0ABED_5577_4F88_AE5F_842FCA797B32_: component=ECU_Composition.Damping
          D_A6B383F7_B581_4F28_BA55_B7062A0A9379_: component=ECU_Composition.DampingFirewall
          D_3DFF91E1_7AFC_4153_A404_8AC3E37DD734_: component=ECU_Composition.DemIf
          D_BFF2A07B_3090_4296_ABF2_D1591FE8CAF0_: component=ECU_Composition.DiagMgr10
          D_B5CF7906_39B9_4691_B0F2_802F488D711B_: component=ECU_Composition.DiagMgr8
          D_53B9067B_BDCD_49D3_B8C1_3DCCF2EF9039_: component=ECU_Composition.DiagMgr9
          D_FAE52953_44D4_4261_959C_24A5F6BA8FF9_: component=ECU_Composition.DiagSvc
          D_B977BC88_5669_49AE_974B_4A290725D421_: component=ECU_Composition.DigHwTrqSENT
          D_600B313C_A37C_4528_9C3C_BD9B1230BA69_: component=ECU_Composition.DigMSB
          D_B56C0208_C9A1_4CF2_BD8F_713E67AAD78C_: component=ECU_Composition.DigPhsReasDiag
          D_7F8F9969_60A3_438C_87EE_212608D785D9_: component=ECU_Composition.ElePwr
          D_9D667EDD_BFAC_4F4B_8104_CF061BE42C92_: component=ECU_Composition.EOTActuatorMng
          D_471ACE2F_424B_4C85_A67C_00529EA8FC9C_: component=ECU_Composition.ePWM2
          D_2C1CAF89_1C7A_4B73_97A8_B67A947D1AF7_: component=ECU_Composition.EtDmpFw
          D_620645F1_2670_4593_9220_220EF30F61FC_: component=ECU_Composition.FltInjection
          D_371BA6CE_0492_43F7_B577_C0CF59D6B190_: component=ECU_Composition.FrqDepDmpnInrtCmp
          D_4ED53FF9_8833_4A47_B28F_9A2E9A253C30_: component=ECU_Composition.Gsod
          D_BA0F4F63_EAF7_49D1_A538_D859A6C05FBA_: component=ECU_Composition.HaitecTrqCmd
          D_159340D1_ED1D_4388_B5FE_8A0565E9972E_: component=ECU_Composition.HighFreqAssist
          D_A4FF533A_7AF8_46A3_BB8B_BF583DC7BE64_: component=ECU_Composition.HiLoadStall
          D_3F60E6F1_2AF9_4EA9_B353_E96D1057D619_: component=ECU_Composition.HwPwUp
          D_723CF942_CAAC_4671_9C2C_FA9BDF92345D_: component=ECU_Composition.HystComp
          D_301B1A35_4DE1_417B_9D57_9EE99B8B750C_: component=ECU_Composition.IoHwAbsDigSig
          D_F0E25EE8_3FC6_4F1C_BAEE_9006415633E3_: component=ECU_Composition.IoHwAbstractionUsr
          D_782B12F8_330C_49A0_96C1_01467D1AD3DF_: component=ECU_Composition.LmtCod
          D_617B25E4_AF0E_4704_86D1_0E6687DABE7A_: component=ECU_Composition.LrnEOT
          D_367D54C9_49A1_484F_A649_074E22429BE3_: component=ECU_Composition.MtrDrvDiag
          D_FBCF84B2_A569_4A58_BDF8_50A921098FE9_: component=ECU_Composition.MtrTempEst
          D_E6BE401B_E46E_4B25_ACE7_E32961603E5B_: component=ECU_Composition.MtrVel
          D_C5357F49_762A_489F_A7F3_66CCA9BF6F46_: component=ECU_Composition.MtrVel2
          D_102CC892_6FA5_4678_8A40_23A731313F3B_: component=ECU_Composition.MtrVel3
          D_A7834DC8_520F_4FD2_9619_E4333A3A0F49_: component=ECU_Composition.Nhet1
          D_0F5E361A_405A_425C_AF8F_3DD442C0139D_: component=ECU_Composition.NtWrap
          D_6C14E912_513D_497C_8D06_0685B2C3FA90_: component=ECU_Composition.OvrVoltMon
          D_A55A9D90_CC2D_44B2_B55D_54C3F39527B1_: component=ECU_Composition.PeakCurrEst
          D_C8D0D855_F67A_4D1F_8673_B30AA9EAB927_: component=ECU_Composition.PICurrCntrl
          D_0A1AFEAB_DA3C_4A6D_BC3D_2EB7036CAB45_: component=ECU_Composition.Polarity
          D_C6F97FAC_5A5A_41A9_8565_79D48DE92A51_: component=ECU_Composition.PwrLmtFuncCr
          D_D3B70E67_12D8_408B_913E_AB86B4F924FC_: component=ECU_Composition.QuadDet
          D_5D0E306F_6110_439C_BD7D_41899168F591_: component=ECU_Composition.Return
          D_E368FBEF_03FC_485D_90A6_DCDEAB3DF918_: component=ECU_Composition.ReturnFirewall
          D_4A2BEFA2_EE0E_4288_B799_CED4380D5412_: component=ECU_Composition.RteErrata
          D_3E6837B7_9FE2_4197_B696_EADB779B762B_: component=ECU_Composition.RteErrata8
          D_86A80C5D_A1A9_4312_BD42_E55D3E05720B_: component=ECU_Composition.RteErrata9
          D_23E033FB_78C4_4E5D_981F_61652454C2B6_: component=ECU_Composition.ShtdnMech
          D_26E47738_5578_4959_A9EF_A920E9B259D5_: component=ECU_Composition.SignlCondn
          D_86F6AB25_832B_4395_AE65_21B517EE3694_: component=ECU_Composition.SrlComInput
          D_2C16A642_37DA_4723_B180_1B5C7B9A59DD_: component=ECU_Composition.SrlComOutput
          D_6F370927_6B4C_4268_BDEC_FC8D1671EF04_: component=ECU_Composition.StabilityComp
          D_48092368_C0CE_4103_9685_C5CD38781A59_: component=ECU_Composition.StabilityComp2
          D_740243BD_F900_4EEE_8B19_C2F3D439C269_: component=ECU_Composition.StaMd
          D_ACB007BC_251D_4BE6_AE86_364A6BCA67B3_: component=ECU_Composition.StaMd8
          D_20B320B6_DD0F_471F_A3A9_C9689EA7DEF1_: component=ECU_Composition.StaMd9
          D_0B3A265F_7BDF_43D6_AEA3_6704B83120D2_: component=ECU_Composition.StOpCtrl
          D_5D5F0B52_F7F6_4D74_AAFA_98961CCE63B3_: component=ECU_Composition.Sweep
          D_EE2384FA_2E65_4698_AC68_C3D0E7374B1D_: component=ECU_Composition.Sweep2
          D_F68E7F06_7CBD_4682_A9FD_43F8C4D5C6CB_: component=ECU_Composition.ThrmlDutyCycle
          D_6257C789_8231_43EA_8768_1B2E185C872A_: component=ECU_Composition.TmprlMon
          D_A76F58E1_0218_4D66_AD1D_EDDEDFE8CAB3_: component=ECU_Composition.TmprlMon2
          D_109D320F_6F29_42C0_9CE0_C864AEC15BC3_: component=ECU_Composition.TqRsDg
          D_767A76B3_914B_4C30_8A34_07FDC1772D80_: component=ECU_Composition.TrqCanc
          D_EB57F99E_B02F_48AF_A1C1_7827F6490E9F_: component=ECU_Composition.TrqCmdScl
          D_574EEB98_F0BF_4B29_9B1F_FAB98468FB07_: component=ECU_Composition.TuningSelAuth
          D_C494D763_5DE0_4CCE_B057_DF89DAF2DE60_: component=ECU_Composition.uDiag
          D_5515B0B4_6D7E_4377_B1FB_80BC4233E981_: component=ECU_Composition.VehDyn
          D_AE230A9D_0217_4A33_A7A3_F3C2DE497C16_: component=ECU_Composition.VehPwrMd
          D_C9B4F0C1_8CED_40A8_9F32_C1C114FDDA55_: component=ECU_Composition.VehSpdLmt
    software composition ECU_Composition: software-composition=ECU_Composition
